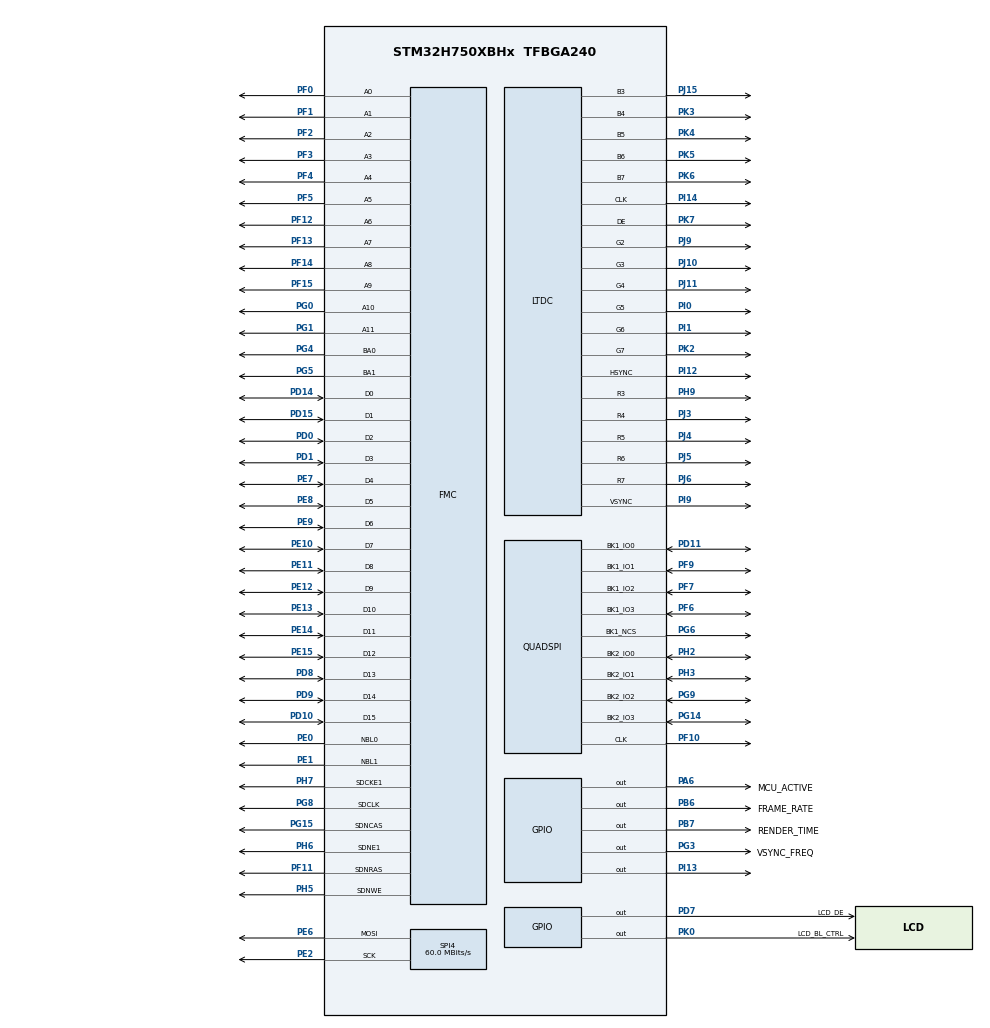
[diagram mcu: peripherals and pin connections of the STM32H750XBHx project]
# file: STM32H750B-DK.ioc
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CORTEX_M7.AccessPermission-Cortex_Memory_Protection_Unit_Region0_Settings=MPU_REGION_FULL_ACCESS
CORTEX_M7.AccessPermission-Cortex_Memory_Protection_Unit_Region1_Settings=MPU_REGION_NO_ACCESS
CORTEX_M7.AccessPermission-Cortex_Memory_Protection_Unit_Region2_Settings=MPU_REGION_FULL_ACCESS
CORTEX_M7.AccessPermission-Cortex_Memory_Protection_Unit_Region4_Settings=MPU_REGION_FULL_ACCESS
CORTEX_M7.BaseAddress-Cortex_Memory_Protection_Unit_Region0_Settings=0x24000000
CORTEX_M7.BaseAddress-Cortex_Memory_Protection_Unit_Region1_Settings=0x90000000
CORTEX_M7.BaseAddress-Cortex_Memory_Protection_Unit_Region2_Settings=0x90000000
CORTEX_M7.BaseAddress-Cortex_Memory_Protection_Unit_Region3_Settings=0xD0000000
CORTEX_M7.BaseAddress-Cortex_Memory_Protection_Unit_Region4_Settings=0xD0000000
CORTEX_M7.CPU_DCache=Enabled
CORTEX_M7.CPU_ICache=Enabled
CORTEX_M7.DisableExec-Cortex_Memory_Protection_Unit_Region0_Settings=MPU_INSTRUCTION_ACCESS_DISABLE
CORTEX_M7.DisableExec-Cortex_Memory_Protection_Unit_Region1_Settings=MPU_INSTRUCTION_ACCESS_DISABLE
CORTEX_M7.DisableExec-Cortex_Memory_Protection_Unit_Region2_Settings=MPU_INSTRUCTION_ACCESS_ENABLE
CORTEX_M7.DisableExec-Cortex_Memory_Protection_Unit_Region3_Settings=MPU_INSTRUCTION_ACCESS_DISABLE
CORTEX_M7.DisableExec-Cortex_Memory_Protection_Unit_Region4_Settings=MPU_INSTRUCTION_ACCESS_DISABLE
CORTEX_M7.Enable-Cortex_Memory_Protection_Unit_Region0_Settings=MPU_REGION_ENABLE
CORTEX_M7.Enable-Cortex_Memory_Protection_Unit_Region1_Settings=MPU_REGION_ENABLE
CORTEX_M7.Enable-Cortex_Memory_Protection_Unit_Region2_Settings=MPU_REGION_ENABLE
CORTEX_M7.Enable-Cortex_Memory_Protection_Unit_Region3_Settings=MPU_REGION_ENABLE
CORTEX_M7.Enable-Cortex_Memory_Protection_Unit_Region4_Settings=MPU_REGION_ENABLE
CORTEX_M7.IsBufferable-Cortex_Memory_Protection_Unit_Region0_Settings=MPU_ACCESS_BUFFERABLE
CORTEX_M7.IsBufferable-Cortex_Memory_Protection_Unit_Region1_Settings=MPU_ACCESS_NOT_BUFFERABLE
CORTEX_M7.IsBufferable-Cortex_Memory_Protection_Unit_Region2_Settings=MPU_ACCESS_BUFFERABLE
CORTEX_M7.IsCacheable-Cortex_Memory_Protection_Unit_Region0_Settings=MPU_ACCESS_CACHEABLE
CORTEX_M7.IsCacheable-Cortex_Memory_Protection_Unit_Region1_Settings=MPU_ACCESS_NOT_CACHEABLE
CORTEX_M7.IsCacheable-Cortex_Memory_Protection_Unit_Region2_Settings=MPU_ACCESS_CACHEABLE
CORTEX_M7.IsCacheable-Cortex_Memory_Protection_Unit_Region4_Settings=MPU_ACCESS_CACHEABLE
CORTEX_M7.IsShareable-Cortex_Memory_Protection_Unit_Region2_Settings=MPU_ACCESS_NOT_SHAREABLE
CORTEX_M7.IsShareable-Cortex_Memory_Protection_Unit_Region4_Settings=MPU_ACCESS_NOT_SHAREABLE
CORTEX_M7.MPU_Control=MPU_PRIVILEGED_DEFAULT
CORTEX_M7.Size-Cortex_Memory_Protection_Unit_Region0_Settings=MPU_REGION_SIZE_512KB
CORTEX_M7.Size-Cortex_Memory_Protection_Unit_Region1_Settings=MPU_REGION_SIZE_256MB
CORTEX_M7.Size-Cortex_Memory_Protection_Unit_Region2_Settings=MPU_REGION_SIZE_128MB
CORTEX_M7.Size-Cortex_Memory_Protection_Unit_Region3_Settings=MPU_REGION_SIZE_256MB
CORTEX_M7.Size-Cortex_Memory_Protection_Unit_Region4_Settings=MPU_REGION_SIZE_32MB
DMA2D.ColorMode=DMA2D_OUTPUT_RGB565
FMC.CASLatency2=FMC_SDRAM_CAS_LATENCY_3
FMC.ColumnBitsNumber2=FMC_SDRAM_COLUMN_BITS_NUM_8
FMC.ExitSelfRefreshDelay2=7
FMC.LoadToActiveDelay2=2
FMC.RCDDelay2=2
FMC.RPDelay2=2
FMC.ReadBurst2=FMC_SDRAM_RBURST_ENABLE
FMC.RowCycleDelay2=7
FMC.SDClockPeriod2=FMC_SDRAM_CLOCK_PERIOD_2
FMC.SelfRefreshTime2=4
FMC.WriteRecoveryTime2=5
FREERTOS.HEAP_NUMBER=4
FREERTOS.Queues01=noteQueue,16,uint8_t,0,Dynamic,NULL,NULL
FREERTOS.Tasks01=defaultTask,24,128,StartDefaultTask,Default,NULL,Dynamic,NULL,NULL;GUITask,24,8192,TouchGFX_Task,As external,NULL,Dynamic,NULL,NULL;playNoteTask,8,128,playNoteTaskFunction,Default,NULL,Dynamic,NULL,NULL
FREERTOS.configTOTAL_HEAP_SIZE=100000
FREERTOS.configUSE_APPLICATION_TASK_TAG=1
FREERTOS.configUSE_IDLE_HOOK=1
FREERTOS.configUSE_MALLOC_FAILED_HOOK=0
JPEG.JPEG_RGB_FORMAT=JPEG_RGB565
LIBJPEG.RGB_ORDERING=BGR
LTDC.ActiveH=272
LTDC.ActiveW=480
LTDC.Alpha_L0=255
LTDC.BlendingFactor1_L0=LTDC_BLENDING_FACTOR1_CA
LTDC.BlendingFactor2_L0=LTDC_BLENDING_FACTOR2_CA
LTDC.HBP=3
LTDC.HSync=40
LTDC.ImageHeight_L0=272
LTDC.ImageWidth_L0=480
LTDC.Layers=0
LTDC.PixelFormat_L0=LTDC_PIXEL_FORMAT_RGB565
LTDC.VBP=3
LTDC.VSync=9
LTDC.WindowX1_L0=480
LTDC.WindowY1_L0=272
Mcu.Family=STM32H7
Mcu.Name=STM32H750XBHx
Mcu.Package=TFBGA240
Mdma.MDMA_Channel6.JPEG_OUTFIFO_TH.0.BlockCount=0
Mdma.MDMA_Channel6.JPEG_OUTFIFO_TH.0.BlockDataLength=0
Mdma.MDMA_Channel6.JPEG_OUTFIFO_TH.0.BufferTransferLength=32
Mdma.MDMA_Channel6.JPEG_OUTFIFO_TH.0.CircularMode=MDMA_LINEAR_LIST
Mdma.MDMA_Channel6.JPEG_OUTFIFO_TH.0.DataAlignment=MDMA_DATAALIGN_PACKENABLE
Mdma.MDMA_Channel6.JPEG_OUTFIFO_TH.0.DestBlockAddressOffset=0
Mdma.MDMA_Channel6.JPEG_OUTFIFO_TH.0.DestBurst=MDMA_DEST_BURST_32BEATS
Mdma.MDMA_Channel6.JPEG_OUTFIFO_TH.0.DestDataSize=MDMA_DEST_DATASIZE_BYTE
Mdma.MDMA_Channel6.JPEG_OUTFIFO_TH.0.DestinationInc=MDMA_DEST_INC_BYTE
Mdma.MDMA_Channel6.JPEG_OUTFIFO_TH.0.DstAddress=0
Mdma.MDMA_Channel6.JPEG_OUTFIFO_TH.0.Endianness=MDMA_LITTLE_ENDIANNESS_PRESERVE
Mdma.MDMA_Channel6.JPEG_OUTFIFO_TH.0.Instance=MDMA_Channel6
Mdma.MDMA_Channel6.JPEG_OUTFIFO_TH.0.MaskAddress=0
Mdma.MDMA_Channel6.JPEG_OUTFIFO_TH.0.MaskData=0
Mdma.MDMA_Channel6.JPEG_OUTFIFO_TH.0.Priority=MDMA_PRIORITY_VERY_HIGH
Mdma.MDMA_Channel6.JPEG_OUTFIFO_TH.0.Rank=First
Mdma.MDMA_Channel6.JPEG_OUTFIFO_TH.0.SourceBlockAddressOffset=0
Mdma.MDMA_Channel6.JPEG_OUTFIFO_TH.0.SourceBurst=MDMA_SOURCE_BURST_32BEATS
Mdma.MDMA_Channel6.JPEG_OUTFIFO_TH.0.SourceDataSize=MDMA_SRC_DATASIZE_WORD
Mdma.MDMA_Channel6.JPEG_OUTFIFO_TH.0.SourceInc=MDMA_SRC_INC_DISABLE
Mdma.MDMA_Channel6.JPEG_OUTFIFO_TH.0.SrcAddress=0
Mdma.MDMA_Channel6.JPEG_OUTFIFO_TH.0.TransferTriggerMode=MDMA_BUFFER_TRANSFER
Mdma.MDMA_Channel6.Request0=JPEG_OUTFIFO_TH
Mdma.MDMA_Channel6.RequestsNb=1
Mdma.MDMA_Channel7.JPEG_INFIFO_TH.0.BlockCount=0
Mdma.MDMA_Channel7.JPEG_INFIFO_TH.0.BlockDataLength=0
Mdma.MDMA_Channel7.JPEG_INFIFO_TH.0.BufferTransferLength=32
Mdma.MDMA_Channel7.JPEG_INFIFO_TH.0.CircularMode=MDMA_LINEAR_LIST
Mdma.MDMA_Channel7.JPEG_INFIFO_TH.0.DataAlignment=MDMA_DATAALIGN_PACKENABLE
Mdma.MDMA_Channel7.JPEG_INFIFO_TH.0.DestBlockAddressOffset=0
Mdma.MDMA_Channel7.JPEG_INFIFO_TH.0.DestBurst=MDMA_DEST_BURST_16BEATS
Mdma.MDMA_Channel7.JPEG_INFIFO_TH.0.DestDataSize=MDMA_DEST_DATASIZE_WORD
Mdma.MDMA_Channel7.JPEG_INFIFO_TH.0.DestinationInc=MDMA_DEST_INC_DISABLE
Mdma.MDMA_Channel7.JPEG_INFIFO_TH.0.DstAddress=0
Mdma.MDMA_Channel7.JPEG_INFIFO_TH.0.Endianness=MDMA_LITTLE_ENDIANNESS_PRESERVE
Mdma.MDMA_Channel7.JPEG_INFIFO_TH.0.Instance=MDMA_Channel7
Mdma.MDMA_Channel7.JPEG_INFIFO_TH.0.MaskAddress=0
Mdma.MDMA_Channel7.JPEG_INFIFO_TH.0.MaskData=0
Mdma.MDMA_Channel7.JPEG_INFIFO_TH.0.Priority=MDMA_PRIORITY_HIGH
Mdma.MDMA_Channel7.JPEG_INFIFO_TH.0.Rank=First
Mdma.MDMA_Channel7.JPEG_INFIFO_TH.0.SourceBlockAddressOffset=0
Mdma.MDMA_Channel7.JPEG_INFIFO_TH.0.SourceBurst=MDMA_SOURCE_BURST_32BEATS
Mdma.MDMA_Channel7.JPEG_INFIFO_TH.0.SourceDataSize=MDMA_SRC_DATASIZE_BYTE
Mdma.MDMA_Channel7.JPEG_INFIFO_TH.0.SourceInc=MDMA_SRC_INC_BYTE
Mdma.MDMA_Channel7.JPEG_INFIFO_TH.0.SrcAddress=0
Mdma.MDMA_Channel7.JPEG_INFIFO_TH.0.TransferTriggerMode=MDMA_BUFFER_TRANSFER
Mdma.MDMA_Channel7.Request0=JPEG_INFIFO_TH
Mdma.MDMA_Channel7.RequestsNb=1
Mdma.RequestSet0=MDMA_Channel7
Mdma.RequestSet1=MDMA_Channel6
Mdma.RequestSetsNb=2
NVIC.DMA2D_IRQn=true\:5\:0\:true\:false\:true\:false\:true\:true\:true
NVIC.JPEG_IRQn=true\:5\:0\:false\:false\:true\:true\:true\:true\:true
NVIC.LTDC_IRQn=true\:5\:0\:true\:false\:true\:false\:true\:true\:true
NVIC.MDMA_IRQn=true\:5\:0\:false\:false\:true\:true\:false\:true\:true
NVIC.PriorityGroup=NVIC_PRIORITYGROUP_4
NVIC.TIM5_IRQn=true\:5\:0\:false\:false\:true\:true\:true\:true\:true
NVIC.TIM6_DAC_IRQn=true\:0\:0\:false\:false\:true\:false\:false\:true\:true
NVIC.TimeBase=TIM6_DAC_IRQn
NVIC.TimeBaseIP=TIM6
PA6.GPIO_Label=MCU_ACTIVE
PA6.GPIO_Speed=GPIO_SPEED_FREQ_VERY_HIGH
PA6.Signal=GPIO_Output
PB6.GPIO_Label=FRAME_RATE
PB6.GPIO_Speed=GPIO_SPEED_FREQ_VERY_HIGH
PB6.Signal=GPIO_Output
PB7.GPIO_Label=RENDER_TIME
PB7.GPIO_Speed=GPIO_SPEED_FREQ_VERY_HIGH
PB7.Signal=GPIO_Output
PD0.Signal=FMC_D2_DA2
PD1.Signal=FMC_D3_DA3
PD10.Signal=FMC_D15_DA15
PD11.GPIO_Speed=GPIO_SPEED_FREQ_VERY_HIGH
PD11.Mode=Dual_Bank
PD11.Signal=QUADSPI_BK1_IO0
PD14.Signal=FMC_D0_DA0
PD15.Signal=FMC_D1_DA1
PD7.GPIO_Label=LCD_DE
PD7.Signal=GPIO_Output
PD8.Signal=FMC_D13_DA13
PD9.Signal=FMC_D14_DA14
PE0.Signal=FMC_NBL0
PE1.Signal=FMC_NBL1
PE10.Signal=FMC_D7_DA7
PE11.Signal=FMC_D8_DA8
PE12.Signal=FMC_D9_DA9
PE13.Signal=FMC_D10_DA10
PE14.Signal=FMC_D11_DA11
PE15.Signal=FMC_D12_DA12
PE2.Mode=TX_Only_Simplex_Unidirect_Master
PE2.Signal=SPI4_SCK
PE6.Mode=TX_Only_Simplex_Unidirect_Master
PE6.Signal=SPI4_MOSI
PE7.Signal=FMC_D4_DA4
PE8.Signal=FMC_D5_DA5
PE9.Signal=FMC_D6_DA6
PF0.Signal=FMC_A0
PF1.Signal=FMC_A1
PF10.GPIO_Speed=GPIO_SPEED_FREQ_VERY_HIGH
PF10.Mode=Dual_Bank
PF10.Signal=QUADSPI_CLK
PF11.Signal=FMC_SDNRAS
PF12.Signal=FMC_A6
PF13.Signal=FMC_A7
PF14.Signal=FMC_A8
PF15.Signal=FMC_A9
PF2.Signal=FMC_A2
PF3.Signal=FMC_A3
PF4.Signal=FMC_A4
PF5.Signal=FMC_A5
PF6.GPIO_Speed=GPIO_SPEED_FREQ_VERY_HIGH
PF6.Mode=Dual_Bank
PF6.Signal=QUADSPI_BK1_IO3
PF7.GPIO_Speed=GPIO_SPEED_FREQ_VERY_HIGH
PF7.Mode=Dual_Bank
PF7.Signal=QUADSPI_BK1_IO2
PF9.GPIO_Speed=GPIO_SPEED_FREQ_VERY_HIGH
PF9.Mode=Dual_Bank
PF9.Signal=QUADSPI_BK1_IO1
PG0.Signal=FMC_A10
PG1.Signal=FMC_A11
PG14.GPIO_Speed=GPIO_SPEED_FREQ_VERY_HIGH
PG14.Mode=Dual_Bank
PG14.Signal=QUADSPI_BK2_IO3
PG15.Signal=FMC_SDNCAS
PG3.GPIO_Label=VSYNC_FREQ
PG3.GPIO_Speed=GPIO_SPEED_FREQ_VERY_HIGH
PG3.Signal=GPIO_Output
PG4.Signal=FMC_A14_BA0
PG5.Signal=FMC_A15_BA1
PG6.GPIO_Speed=GPIO_SPEED_FREQ_VERY_HIGH
PG6.Mode=Enable Chip Select 1 for both banks
PG6.Signal=QUADSPI_BK1_NCS
PG8.Signal=FMC_SDCLK
PG9.GPIO_Speed=GPIO_SPEED_FREQ_VERY_HIGH
PG9.Mode=Dual_Bank
PG9.Signal=QUADSPI_BK2_IO2
PH0-OSC_IN\ (PH0).Mode=HSE-External-Oscillator
PH0-OSC_IN\ (PH0).Signal=RCC_OSC_IN
PH1-OSC_OUT\ (PH1).Mode=HSE-External-Oscillator
PH1-OSC_OUT\ (PH1).Signal=RCC_OSC_OUT
PH2.GPIO_Speed=GPIO_SPEED_FREQ_VERY_HIGH
PH2.Mode=Dual_Bank
PH2.Signal=QUADSPI_BK2_IO0
PH3.GPIO_Speed=GPIO_SPEED_FREQ_VERY_HIGH
PH3.Mode=Dual_Bank
PH3.Signal=QUADSPI_BK2_IO1
PH5.Signal=FMC_SDNWE
PH6.Mode=SdramChipSelect2_2
PH6.Signal=FMC_SDNE1
PH7.Mode=SdramChipSelect2_2
PH7.Signal=FMC_SDCKE1
PH9.GPIO_Speed=GPIO_SPEED_FREQ_HIGH
PH9.Mode=RGB565
PH9.Signal=LTDC_R3
PI0.GPIO_Speed=GPIO_SPEED_FREQ_HIGH
PI0.Mode=RGB565
PI0.Signal=LTDC_G5
PI1.GPIO_Speed=GPIO_SPEED_FREQ_HIGH
PI1.Mode=RGB565
PI1.Signal=LTDC_G6
PI12.GPIO_Speed=GPIO_SPEED_FREQ_HIGH
PI12.Mode=RGB565
PI12.Signal=LTDC_HSYNC
PI13.GPIO_ModeDefaultOutputPP=GPIO_MODE_OUTPUT_PP
PI13.Signal=GPIO_Output
PI14.GPIO_Speed=GPIO_SPEED_FREQ_HIGH
PI14.Mode=RGB565
PI14.Signal=LTDC_CLK
PI15.GPIO_Speed=GPIO_SPEED_FREQ_HIGH
PI15.Signal=LTDC_R0
PI9.GPIO_Speed=GPIO_SPEED_FREQ_HIGH
PI9.Mode=RGB565
PI9.Signal=LTDC_VSYNC
PJ0.GPIO_Speed=GPIO_SPEED_FREQ_HIGH
PJ0.Signal=LTDC_R1
PJ1.GPIO_Speed=GPIO_SPEED_FREQ_HIGH
PJ1.Signal=LTDC_R2
PJ10.GPIO_Speed=GPIO_SPEED_FREQ_HIGH
PJ10.Mode=RGB565
PJ10.Signal=LTDC_G3
PJ11.GPIO_Speed=GPIO_SPEED_FREQ_HIGH
PJ11.Mode=RGB565
PJ11.Signal=LTDC_G4
PJ12.GPIO_Speed=GPIO_SPEED_FREQ_HIGH
PJ12.Signal=LTDC_B0
PJ13.GPIO_Speed=GPIO_SPEED_FREQ_HIGH
PJ13.Signal=LTDC_B1
PJ14.GPIO_Speed=GPIO_SPEED_FREQ_HIGH
PJ14.Signal=LTDC_B2
PJ15.GPIO_Speed=GPIO_SPEED_FREQ_HIGH
PJ15.Mode=RGB565
PJ15.Signal=LTDC_B3
PJ3.GPIO_Speed=GPIO_SPEED_FREQ_HIGH
PJ3.Mode=RGB565
PJ3.Signal=LTDC_R4
PJ4.GPIO_Speed=GPIO_SPEED_FREQ_HIGH
PJ4.Mode=RGB565
PJ4.Signal=LTDC_R5
PJ5.GPIO_Speed=GPIO_SPEED_FREQ_HIGH
PJ5.Mode=RGB565
PJ5.Signal=LTDC_R6
PJ6.GPIO_Speed=GPIO_SPEED_FREQ_HIGH
PJ6.Mode=RGB565
PJ6.Signal=LTDC_R7
PJ7.GPIO_Speed=GPIO_SPEED_FREQ_HIGH
PJ7.Signal=LTDC_G0
PJ8.GPIO_Speed=GPIO_SPEED_FREQ_HIGH
PJ8.Signal=LTDC_G1
PJ9.GPIO_Speed=GPIO_SPEED_FREQ_HIGH
PJ9.Mode=RGB565
PJ9.Signal=LTDC_G2
PK0.GPIO_Label=LCD_BL_CTRL
PK0.PinState=GPIO_PIN_SET
PK0.Signal=GPIO_Output
PK2.GPIO_Speed=GPIO_SPEED_FREQ_HIGH
PK2.Mode=RGB565
PK2.Signal=LTDC_G7
PK3.GPIO_Speed=GPIO_SPEED_FREQ_HIGH
PK3.Mode=RGB565
PK3.Signal=LTDC_B4
PK4.GPIO_Speed=GPIO_SPEED_FREQ_HIGH
PK4.Mode=RGB565
PK4.Signal=LTDC_B5
PK5.GPIO_Speed=GPIO_SPEED_FREQ_HIGH
PK5.Mode=RGB565
PK5.Signal=LTDC_B6
PK6.GPIO_Speed=GPIO_SPEED_FREQ_HIGH
PK6.Mode=RGB565
PK6.Signal=LTDC_B7
PK7.GPIO_Speed=GPIO_SPEED_FREQ_HIGH
PK7.Mode=RGB565
PK7.Signal=LTDC_DE
ProjectManager.HeapSize=0x1000
ProjectManager.StackSize=0x1000
ProjectManager.TargetToolchain=STM32CubeIDE
QUADSPI.ChipSelectHighTime=QSPI_CS_HIGH_TIME_4_CYCLE
QUADSPI.ClockMode=QSPI_CLOCK_MODE_0
QUADSPI.ClockPrescaler=3
QUADSPI.FlashSize=26
QUADSPI.SampleShifting=QSPI_SAMPLE_SHIFTING_NONE
RCC.ADCFreq_Value=50390625
RCC.APB1Freq_Value=120000000
RCC.APB2Freq_Value=120000000
RCC.APB3Freq_Value=120000000
RCC.APB4Freq_Value=120000000
RCC.CortexFreq_Value=480000000
RCC.D1PPRE=RCC_APB3_DIV2
RCC.D2PPRE1=RCC_APB1_DIV2
RCC.D2PPRE2=RCC_APB2_DIV2
RCC.D3PPRE=RCC_APB4_DIV2
RCC.DIVM1=5
RCC.DIVM3=5
RCC.DIVN1=192
RCC.DIVN3=160
RCC.DIVQ1=4
RCC.DIVR3=93
RCC.HCLKFreq_Value=240000000
RCC.HPRE=RCC_HCLK_DIV2
RCC.PLL3FRACN=0
RCC.PLLSourceVirtual=RCC_PLLSOURCE_HSE
RCC.SYSCLKFreq_VALUE=480000000
RCC.SYSCLKSource=RCC_SYSCLKSOURCE_PLLCLK
RCC.USBFreq_Value=240000000
SH.FMC_A0.0=FMC_A0,12b-sda2
SH.FMC_A1.0=FMC_A1,12b-sda2
SH.FMC_A10.0=FMC_A10,12b-sda2
SH.FMC_A11.0=FMC_A11,12b-sda2
SH.FMC_A14_BA0.0=FMC_BA0,FourSdramBanks2
SH.FMC_A15_BA1.0=FMC_BA1,FourSdramBanks2
SH.FMC_A2.0=FMC_A2,12b-sda2
SH.FMC_A3.0=FMC_A3,12b-sda2
SH.FMC_A4.0=FMC_A4,12b-sda2
SH.FMC_A5.0=FMC_A5,12b-sda2
SH.FMC_A6.0=FMC_A6,12b-sda2
SH.FMC_A7.0=FMC_A7,12b-sda2
SH.FMC_A8.0=FMC_A8,12b-sda2
SH.FMC_A9.0=FMC_A9,12b-sda2
SH.FMC_D0_DA0.0=FMC_D0,sd-16b-d2
SH.FMC_D10_DA10.0=FMC_D10,sd-16b-d2
SH.FMC_D11_DA11.0=FMC_D11,sd-16b-d2
SH.FMC_D12_DA12.0=FMC_D12,sd-16b-d2
SH.FMC_D13_DA13.0=FMC_D13,sd-16b-d2
SH.FMC_D14_DA14.0=FMC_D14,sd-16b-d2
SH.FMC_D15_DA15.0=FMC_D15,sd-16b-d2
SH.FMC_D1_DA1.0=FMC_D1,sd-16b-d2
SH.FMC_D2_DA2.0=FMC_D2,sd-16b-d2
SH.FMC_D3_DA3.0=FMC_D3,sd-16b-d2
SH.FMC_D4_DA4.0=FMC_D4,sd-16b-d2
SH.FMC_D5_DA5.0=FMC_D5,sd-16b-d2
SH.FMC_D6_DA6.0=FMC_D6,sd-16b-d2
SH.FMC_D7_DA7.0=FMC_D7,sd-16b-d2
SH.FMC_D8_DA8.0=FMC_D8,sd-16b-d2
SH.FMC_D9_DA9.0=FMC_D9,sd-16b-d2
SH.FMC_NBL0.0=FMC_NBL0,Sd2ByteEnable2
SH.FMC_NBL1.0=FMC_NBL1,Sd2ByteEnable2
SH.FMC_SDCLK.0=FMC_SDCLK,12b-sda2
SH.FMC_SDNCAS.0=FMC_SDNCAS,12b-sda2
SH.FMC_SDNRAS.0=FMC_SDNRAS,12b-sda2
SH.FMC_SDNWE.0=FMC_SDNWE,12b-sda2
SPI4.CalculateBaudRate=60.0 MBits/s
SPI4.Direction=SPI_DIRECTION_2LINES_TXONLY
SPI4.Mode=SPI_MODE_MASTER
SPI4.VirtualType=VM_MASTER
STMicroelectronics.X-CUBE-TOUCHGFX.4.24.0.ApplicationCcGraphicsJjApplication=TouchGFXOoGenerator
STMicroelectronics.X-CUBE-TOUCHGFX.4.24.0.tgfx_address1=0xD0000000
STMicroelectronics.X-CUBE-TOUCHGFX.4.24.0.tgfx_address2=0xD003FC00
STMicroelectronics.X-CUBE-TOUCHGFX.4.24.0.tgfx_buffering_strategy=Double
STMicroelectronics.X-CUBE-TOUCHGFX.4.24.0.tgfx_display_interface=disp_ltdc
STMicroelectronics.X-CUBE-TOUCHGFX.4.24.0.tgfx_hardware_accelerator=dma_2d
STMicroelectronics.X-CUBE-TOUCHGFX.4.24.0.tgfx_location=Allocate
STMicroelectronics.X-CUBE-TOUCHGFX.4.24.0.tgfx_pixel_format=RGB565\:16
STMicroelectronics.X-CUBE-TOUCHGFX.4.24.0.tgfx_vector_fonts=Enabled
STMicroelectronics.X-CUBE-TOUCHGFX.4.24.0.tgfx_vector_rendering=Software
STMicroelectronics.X-CUBE-TOUCHGFX.4.24.0.tgfx_video=Hardware
STMicroelectronics.X-CUBE-TOUCHGFX.4.24.0.tgfx_video_height=288
STMicroelectronics.X-CUBE-TOUCHGFX.4.24.0.tgfx_video_strategy=0
STMicroelectronics.X-CUBE-TOUCHGFX.4.24.0.tgfx_video_width=480
STMicroelectronics.X-CUBE-TOUCHGFX.4.24.0.tgfx_vsync=vsync_ltdc
TIM5.AutoReloadPreload=TIM_AUTORELOAD_PRELOAD_ENABLE
VP_CRC_VS_CRC.Mode=CRC_Activate
VP_DMA2D_VS_DMA2D.Mode=DMA2D_Activate
VP_FREERTOS_VS_CMSIS_V2.Mode=CMSIS_V2
VP_JPEG_VS_JPEG.Mode=JPEG_Activate
VP_LIBJPEG_VS_JPEGLIB.Mode=Enabled
VP_MEMORYMAP_VS_MEMORYMAP.Mode=CurAppReg
VP_STMicroelectronics.X-CUBE-TOUCHGFX_VS_GraphicsJjApplication_4.24.0.Mode=GraphicsJjApplication
VP_SYS_VS_tim6.Mode=TIM6
VP_TIM1_VS_ClockSourceINT.Mode=Internal
VP_TIM5_VS_ClockSourceINT.Mode=Internal
board=custom

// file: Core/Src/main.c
/* USER CODE BEGIN Header */
/**
  ******************************************************************************
  * @file           : main.c
  * @brief          : Main program body
  ******************************************************************************
  * @attention
  *
  * <h2><center>&copy; Copyright (c) 2020 STMicroelectronics.
  * All rights reserved.</center></h2>
  *
  * This software component is licensed by ST under Ultimate Liberty license
  * SLA0044, the "License"; You may not use this file except in compliance with
  * the License. You may obtain a copy of the License at:
  *                             www.st.com/SLA0044
  *
  ******************************************************************************
  */
/* USER CODE END Header */
#include "main.h"
#include "cmsis_os.h"
#include "libjpeg.h"
#include "app_touchgfx.h"

/* USER CODE BEGIN Includes */
#include "stm32h750b_discovery_qspi.h"
#include "stm32h750b_discovery_sdram.h"
/* USER CODE END Includes */

/* USER CODE BEGIN PTD */
#define F_SAMP 20000
#define ARR_SIZE 1024

/* USER CODE END PTD */

/* USER CODE BEGIN PM */
uint32_t bitmask;
uint16_t start;
uint32_t outData = 0x8000;
uint32_t tableIndex = 0;
uint32_t step = 0;
uint16_t state = 0;

const uint16_t sine_table[1024] = {
0x7FFF,0x80C8,0x8191,0x825A,0x8323,0x83EC,0x84B5,
0x857E,0x8647,0x8710,0x87D8,0x88A1,0x8969,0x8A32,
0x8AFA,0x8BC3,0x8C8B,0x8D53,0x8E1B,0x8EE2,0x8FAA,
0x9071,0x9139,0x9200,0x92C7,0x938E,0x9454,0x951B,
0x95E1,0x96A7,0x976D,0x9832,0x98F8,0x99BD,0x9A81,
0x9B46,0x9C0A,0x9CCE,0x9D92,0x9E56,0x9F19,0x9FDC,
0xA09E,0xA160,0xA222,0xA2E4,0xA3A5,0xA466,0xA527,
0xA5E7,0xA6A7,0xA766,0xA825,0xA8E4,0xA9A2,0xAA60,
0xAB1E,0xABDB,0xAC98,0xAD54,0xAE10,0xAECB,0xAF86,
0xB040,0xB0FA,0xB1B4,0xB26D,0xB325,0xB3DE,0xB495,
0xB54C,0xB603,0xB6B9,0xB76E,0xB823,0xB8D8,0xB98B,
0xBA3F,0xBAF1,0xBBA4,0xBC55,0xBD06,0xBDB7,0xBE67,
0xBF16,0xBFC4,0xC072,0xC120,0xC1CD,0xC279,0xC324,
0xC3CF,0xC479,0xC523,0xC5CC,0xC674,0xC71B,0xC7C2,
0xC868,0xC90E,0xC9B3,0xCA57,0xCAFA,0xCB9C,0xCC3E,
0xCCDF,0xCD80,0xCE1F,0xCEBE,0xCF5C,0xCFFA,0xD096,
0xD132,0xD1CD,0xD267,0xD301,0xD39A,0xD431,0xD4C8,
0xD55F,0xD5F4,0xD689,0xD71C,0xD7AF,0xD841,0xD8D2,
0xD963,0xD9F2,0xDA81,0xDB0E,0xDB9B,0xDC27,0xDCB2,
0xDD3D,0xDDC6,0xDE4E,0xDED6,0xDF5C,0xDFE2,0xE067,
0xE0EA,0xE16D,0xE1EF,0xE270,0xE2F0,0xE36F,0xE3ED,
0xE46B,0xE4E7,0xE562,0xE5DC,0xE655,0xE6CE,0xE745,
0xE7BB,0xE831,0xE8A5,0xE918,0xE98A,0xE9FC,0xEA6C,
0xEADB,0xEB49,0xEBB6,0xEC22,0xEC8D,0xECF7,0xED60,
0xEDC8,0xEE2F,0xEE95,0xEEFA,0xEF5D,0xEFC0,0xF021,
0xF082,0xF0E1,0xF13F,0xF19C,0xF1F8,0xF253,0xF2AD,
0xF306,0xF35D,0xF3B4,0xF409,0xF45E,0xF4B1,0xF503,
0xF554,0xF5A4,0xF5F2,0xF640,0xF68C,0xF6D7,0xF721,
0xF76A,0xF7B2,0xF7F9,0xF83E,0xF883,0xF8C6,0xF908,
0xF949,0xF988,0xF9C7,0xFA04,0xFA40,0xFA7B,0xFAB5,
0xFAED,0xFB25,0xFB5B,0xFB90,0xFBC4,0xFBF7,0xFC28,
0xFC58,0xFC87,0xFCB5,0xFCE2,0xFD0D,0xFD38,0xFD61,
0xFD88,0xFDAF,0xFDD4,0xFDF9,0xFE1C,0xFE3D,0xFE5E,
0xFE7D,0xFE9B,0xFEB8,0xFED4,0xFEEE,0xFF08,0xFF20,
0xFF36,0xFF4C,0xFF60,0xFF73,0xFF85,0xFF96,0xFFA5,
0xFFB3,0xFFC0,0xFFCC,0xFFD7,0xFFE0,0xFFE8,0xFFEF,
0xFFF4,0xFFF8,0xFFFC,0xFFFD,0xFFFE,0xFFFD,0xFFFC,
0xFFF8,0xFFF4,0xFFEF,0xFFE8,0xFFE0,0xFFD7,0xFFCC,
0xFFC0,0xFFB3,0xFFA5,0xFF96,0xFF85,0xFF73,0xFF60,
0xFF4C,0xFF36,0xFF20,0xFF08,0xFEEE,0xFED4,0xFEB8,
0xFE9B,0xFE7D,0xFE5E,0xFE3D,0xFE1C,0xFDF9,0xFDD4,
0xFDAF,0xFD88,0xFD61,0xFD38,0xFD0D,0xFCE2,0xFCB5,
0xFC87,0xFC58,0xFC28,0xFBF7,0xFBC4,0xFB90,0xFB5B,
0xFB25,0xFAED,0xFAB5,0xFA7B,0xFA40,0xFA04,0xF9C7,
0xF988,0xF949,0xF908,0xF8C6,0xF883,0xF83E,0xF7F9,
0xF7B2,0xF76A,0xF721,0xF6D7,0xF68C,0xF640,0xF5F2,
0xF5A4,0xF554,0xF503,0xF4B1,0xF45E,0xF409,0xF3B4,
0xF35D,0xF306,0xF2AD,0xF253,0xF1F8,0xF19C,0xF13F,
0xF0E1,0xF082,0xF021,0xEFC0,0xEF5D,0xEEFA,0xEE95,
0xEE2F,0xEDC8,0xED60,0xECF7,0xEC8D,0xEC22,0xEBB6,
0xEB49,0xEADB,0xEA6C,0xE9FC,0xE98A,0xE918,0xE8A5,
0xE831,0xE7BB,0xE745,0xE6CE,0xE655,0xE5DC,0xE562,
0xE4E7,0xE46B,0xE3ED,0xE36F,0xE2F0,0xE270,0xE1EF,
0xE16D,0xE0EA,0xE067,0xDFE2,0xDF5C,0xDED6,0xDE4E,
0xDDC6,0xDD3D,0xDCB2,0xDC27,0xDB9B,0xDB0E,0xDA81,
0xD9F2,0xD963,0xD8D2,0xD841,0xD7AF,0xD71C,0xD689,
0xD5F4,0xD55F,0xD4C8,0xD431,0xD39A,0xD301,0xD267,
0xD1CD,0xD132,0xD096,0xCFFA,0xCF5C,0xCEBE,0xCE1F,
0xCD80,0xCCDF,0xCC3E,0xCB9C,0xCAFA,0xCA57,0xC9B3,
0xC90E,0xC868,0xC7C2,0xC71B,0xC674,0xC5CC,0xC523,
0xC479,0xC3CF,0xC324,0xC279,0xC1CD,0xC120,0xC072,
0xBFC4,0xBF16,0xBE67,0xBDB7,0xBD06,0xBC55,0xBBA4,
0xBAF1,0xBA3F,0xB98B,0xB8D8,0xB823,0xB76E,0xB6B9,
0xB603,0xB54C,0xB495,0xB3DE,0xB325,0xB26D,0xB1B4,
0xB0FA,0xB040,0xAF86,0xAECB,0xAE10,0xAD54,0xAC98,
0xABDB,0xAB1E,0xAA60,0xA9A2,0xA8E4,0xA825,0xA766,
0xA6A7,0xA5E7,0xA527,0xA466,0xA3A5,0xA2E4,0xA222,
0xA160,0xA09E,0x9FDC,0x9F19,0x9E56,0x9D92,0x9CCE,
0x9C0A,0x9B46,0x9A81,0x99BD,0x98F8,0x9832,0x976D,
0x96A7,0x95E1,0x951B,0x9454,0x938E,0x92C7,0x9200,
0x9139,0x9071,0x8FAA,0x8EE2,0x8E1B,0x8D53,0x8C8B,
0x8BC3,0x8AFA,0x8A32,0x8969,0x88A1,0x87D8,0x8710,
0x8647,0x857E,0x84B5,0x83EC,0x8323,0x825A,0x8191,
0x80C8,0x7FFF,0x7F36,0x7E6D,0x7DA4,0x7CDB,0x7C12,
0x7B49,0x7A80,0x79B7,0x78EE,0x7826,0x775D,0x7695,
0x75CC,0x7504,0x743B,0x7373,0x72AB,0x71E3,0x711C,
0x7054,0x6F8D,0x6EC5,0x6DFE,0x6D37,0x6C70,0x6BAA,
0x6AE3,0x6A1D,0x6957,0x6891,0x67CC,0x6706,0x6641,
0x657D,0x64B8,0x63F4,0x6330,0x626C,0x61A8,0x60E5,
0x6022,0x5F60,0x5E9E,0x5DDC,0x5D1A,0x5C59,0x5B98,
0x5AD7,0x5A17,0x5957,0x5898,0x57D9,0x571A,0x565C,
0x559E,0x54E0,0x5423,0x5366,0x52AA,0x51EE,0x5133,
0x5078,0x4FBE,0x4F04,0x4E4A,0x4D91,0x4CD9,0x4C20,
0x4B69,0x4AB2,0x49FB,0x4945,0x4890,0x47DB,0x4726,
0x4673,0x45BF,0x450D,0x445A,0x43A9,0x42F8,0x4247,
0x4197,0x40E8,0x403A,0x3F8C,0x3EDE,0x3E31,0x3D85,
0x3CDA,0x3C2F,0x3B85,0x3ADB,0x3A32,0x398A,0x38E3,
0x383C,0x3796,0x36F0,0x364B,0x35A7,0x3504,0x3462,
0x33C0,0x331F,0x327E,0x31DF,0x3140,0x30A2,0x3004,
0x2F68,0x2ECC,0x2E31,0x2D97,0x2CFD,0x2C64,0x2BCD,
0x2B36,0x2A9F,0x2A0A,0x2975,0x28E2,0x284F,0x27BD,
0x272C,0x269B,0x260C,0x257D,0x24F0,0x2463,0x23D7,
0x234C,0x22C1,0x2238,0x21B0,0x2128,0x20A2,0x201C,
0x1F97,0x1F14,0x1E91,0x1E0F,0x1D8E,0x1D0E,0x1C8F,
0x1C11,0x1B93,0x1B17,0x1A9C,0x1A22,0x19A9,0x1930,
0x18B9,0x1843,0x17CD,0x1759,0x16E6,0x1674,0x1602,
0x1592,0x1523,0x14B5,0x1448,0x13DC,0x1371,0x1307,
0x129E,0x1236,0x11CF,0x1169,0x1104,0x10A1,0x103E,
0x0FDD,0x0F7C,0x0F1D,0x0EBF,0x0E62,0x0E06,0x0DAB,
0x0D51,0x0CF8,0x0CA1,0x0C4A,0x0BF5,0x0BA0,0x0B4D,
0x0AFB,0x0AAA,0x0A5A,0x0A0C,0x09BE,0x0972,0x0927,
0x08DD,0x0894,0x084C,0x0805,0x07C0,0x077B,0x0738,
0x06F6,0x06B5,0x0676,0x0637,0x05FA,0x05BE,0x0583,
0x0549,0x0511,0x04D9,0x04A3,0x046E,0x043A,0x0407,
0x03D6,0x03A6,0x0377,0x0349,0x031C,0x02F1,0x02C6,
0x029D,0x0276,0x024F,0x022A,0x0205,0x01E2,0x01C1,
0x01A0,0x0181,0x0163,0x0146,0x012A,0x0110,0x00F6,
0x00DE,0x00C8,0x00B2,0x009E,0x008B,0x0079,0x0068,
0x0059,0x004B,0x003E,0x0032,0x0027,0x001E,0x0016,
0x000F,0x000A,0x0006,0x0002,0x0001,0x0000,0x0001,
0x0002,0x0006,0x000A,0x000F,0x0016,0x001E,0x0027,
0x0032,0x003E,0x004B,0x0059,0x0068,0x0079,0x008B,
0x009E,0x00B2,0x00C8,0x00DE,0x00F6,0x0110,0x012A,
0x0146,0x0163,0x0181,0x01A0,0x01C1,0x01E2,0x0205,
0x022A,0x024F,0x0276,0x029D,0x02C6,0x02F1,0x031C,
0x0349,0x0377,0x03A6,0x03D6,0x0407,0x043A,0x046E,
0x04A3,0x04D9,0x0511,0x0549,0x0583,0x05BE,0x05FA,
0x0637,0x0676,0x06B5,0x06F6,0x0738,0x077B,0x07C0,
0x0805,0x084C,0x0894,0x08DD,0x0927,0x0972,0x09BE,
0x0A0C,0x0A5A,0x0AAA,0x0AFB,0x0B4D,0x0BA0,0x0BF5,
0x0C4A,0x0CA1,0x0CF8,0x0D51,0x0DAB,0x0E06,0x0E62,
0x0EBF,0x0F1D,0x0F7C,0x0FDD,0x103E,0x10A1,0x1104,
0x1169,0x11CF,0x1236,0x129E,0x1307,0x1371,0x13DC,
0x1448,0x14B5,0x1523,0x1592,0x1602,0x1674,0x16E6,
0x1759,0x17CD,0x1843,0x18B9,0x1930,0x19A9,0x1A22,
0x1A9C,0x1B17,0x1B93,0x1C11,0x1C8F,0x1D0E,0x1D8E,
0x1E0F,0x1E91,0x1F14,0x1F97,0x201C,0x20A2,0x2128,
0x21B0,0x2238,0x22C1,0x234C,0x23D7,0x2463,0x24F0,
0x257D,0x260C,0x269B,0x272C,0x27BD,0x284F,0x28E2,
0x2975,0x2A0A,0x2A9F,0x2B36,0x2BCD,0x2C64,0x2CFD,
0x2D97,0x2E31,0x2ECC,0x2F68,0x3004,0x30A2,0x3140,
0x31DF,0x327E,0x331F,0x33C0,0x3462,0x3504,0x35A7,
0x364B,0x36F0,0x3796,0x383C,0x38E3,0x398A,0x3A32,
0x3ADB,0x3B85,0x3C2F,0x3CDA,0x3D85,0x3E31,0x3EDE,
0x3F8C,0x403A,0x40E8,0x4197,0x4247,0x42F8,0x43A9,
0x445A,0x450D,0x45BF,0x4673,0x4726,0x47DB,0x4890,
0x4945,0x49FB,0x4AB2,0x4B69,0x4C20,0x4CD9,0x4D91,
0x4E4A,0x4F04,0x4FBE,0x5078,0x5133,0x51EE,0x52AA,
0x5366,0x5423,0x54E0,0x559E,0x565C,0x571A,0x57D9,
0x5898,0x5957,0x5A17,0x5AD7,0x5B98,0x5C59,0x5D1A,
0x5DDC,0x5E9E,0x5F60,0x6022,0x60E5,0x61A8,0x626C,
0x6330,0x63F4,0x64B8,0x657D,0x6641,0x6706,0x67CC,
0x6891,0x6957,0x6A1D,0x6AE3,0x6BAA,0x6C70,0x6D37,
0x6DFE,0x6EC5,0x6F8D,0x7054,0x711C,0x71E3,0x72AB,
0x7373,0x743B,0x7504,0x75CC,0x7695,0x775D,0x7826,
0x78EE,0x79B7,0x7A80,0x7B49,0x7C12,0x7CDB,0x7DA4,
0x7E6D,0x7F36};

const uint16_t wave1_table[ARR_SIZE] = {
32767,33370,33973,34576,35177,35778,36378,36977,
37574,38169,38762,39353,39942,40528,41111,41692,
42269,42843,43413,43979,44541,45099,45652,46201,
46745,47284,47818,48347,48870,49387,49898,50404,
50903,51395,51882,52361,52834,53299,53758,54209,
54652,55089,55517,55938,56350,56755,57151,57539,
57919,58290,58653,59007,59352,59688,60016,60334,
60643,60943,61234,61516,61788,62051,62304,62548,
62783,63007,63223,63428,63625,63811,63988,64155,
64313,64460,64599,64727,64846,64956,65055,65146,
65226,65298,65359,65412,65455,65488,65513,65528,
65534,65531,65519,65498,65468,65429,65381,65325,
65260,65187,65105,65015,64917,64810,64696,64574,
64443,64305,64160,64007,63846,63679,63504,63322,
63133,62937,62735,62526,62310,62088,61860,61626,
61386,61140,60889,60631,60369,60101,59828,59550,
59266,58979,58686,58389,58088,57782,57472,57158,
56840,56519,56194,55865,55534,55199,54860,54519,
54175,53829,53479,53128,52774,52417,52059,51699,
51337,50973,50607,50240,49872,49502,49132,48760,
48387,48014,47640,47265,46889,46514,46138,45761,
45385,45009,44633,44257,43881,43505,43130,42756,
42382,42009,41637,41266,40895,40526,40158,39790,
39425,39060,38697,38335,37975,37616,37260,36904,
36551,36199,35849,35502,35156,34812,34470,34131,
33793,33458,33125,32794,32466,32140,31816,31495,
31176,30860,30547,30236,29927,29621,29318,29018,
28720,28425,28132,27843,27556,27272,26990,26712,
26436,26164,25894,25626,25362,25101,24842,24587,
24334,24084,23837,23593,23352,23114,22878,22646,
22416,22189,21966,21745,21527,21311,21099,20889,
20683,20479,20278,20080,19885,19692,19502,19315,
19131,18950,18771,18595,18422,18251,18083,17918,
17756,17596,17439,17284,17132,16983,16836,16692,
16550,16411,16274,16140,16008,15879,15752,15628,
15506,15386,15269,15154,15042,14932,14824,14718,
14615,14514,14415,14319,14225,14133,14043,13955,
13870,13786,13705,13626,13549,13474,13401,13330,
13262,13195,13130,13067,13007,12948,12891,12836,
12783,12732,12683,12636,12591,12547,12505,12466,
12428,12392,12358,12325,12294,12266,12238,12213,
12190,12168,12148,12129,12113,12098,12085,12073,
12064,12056,12049,12044,12041,12040,12040,12042,
12046,12051,12058,12066,12076,12088,12101,12116,
12133,12151,12171,12192,12215,12240,12266,12294,
12323,12354,12386,12420,12456,12493,12532,12572,
12614,12657,12702,12749,12797,12846,12897,12950,
13004,13060,13117,13176,13237,13299,13362,13427,
13494,13562,13632,13703,13776,13850,13926,14003,
14082,14162,14244,14327,14412,14499,14587,14676,
14767,14860,14954,15049,15146,15245,15345,15446,
15549,15654,15760,15867,15976,16086,16198,16311,
16426,16543,16660,16779,16900,17022,17146,17270,
17397,17525,17654,17784,17916,18050,18184,18320,
18458,18597,18737,18878,19021,19165,19311,19458,
19606,19755,19906,20058,20211,20366,20521,20678,
20836,20996,21156,21318,21481,21645,21810,21976,
22144,22312,22482,22653,22824,22997,23171,23346,
23521,23698,23876,24055,24234,24415,24596,24778,
24962,25146,25330,25516,25702,25890,26077,26266,
26455,26645,26836,27028,27220,27412,27605,27799,
27994,28188,28384,28580,28776,28973,29170,29368,
29566,29764,29963,30162,30361,30560,30760,30960,
31160,31361,31561,31762,31963,32164,32365,32566,
32767,32968,33169,33370,33571,33772,33973,34173,
34374,34574,34774,34974,35173,35372,35571,35770,
35968,36166,36364,36561,36758,36954,37150,37346,
37540,37735,37929,38122,38314,38506,38698,38889,
39079,39268,39457,39644,39832,40018,40204,40388,
40572,40756,40938,41119,41300,41479,41658,41836,
42013,42188,42363,42537,42710,42881,43052,43222,
43390,43558,43724,43889,44053,44216,44378,44538,
44698,44856,45013,45168,45323,45476,45628,45779,
45928,46076,46223,46369,46513,46656,46797,46937,
47076,47214,47350,47484,47618,47750,47880,48009,
48137,48264,48388,48512,48634,48755,48874,48991,
49108,49223,49336,49448,49558,49667,49774,49880,
49985,50088,50189,50289,50388,50485,50580,50674,
50767,50858,50947,51035,51122,51207,51290,51372,
51452,51531,51608,51684,51758,51831,51902,51972,
52040,52107,52172,52235,52297,52358,52417,52474,
52530,52584,52637,52688,52737,52785,52832,52877,
52920,52962,53002,53041,53078,53114,53148,53180,
53211,53240,53268,53294,53319,53342,53363,53383,
53401,53418,53433,53446,53458,53468,53476,53483,
53488,53492,53494,53494,53493,53490,53485,53478,
53470,53461,53449,53436,53421,53405,53386,53366,
53344,53321,53296,53268,53240,53209,53176,53142,
53106,53068,53029,52987,52943,52898,52851,52802,
52751,52698,52643,52586,52527,52467,52404,52339,
52272,52204,52133,52060,51985,51908,51829,51748,
51664,51579,51491,51401,51309,51215,51119,51020,
50919,50816,50710,50602,50492,50380,50265,50148,
50028,49906,49782,49655,49526,49394,49260,49123,
48984,48842,48698,48551,48402,48250,48095,47938,
47778,47616,47451,47283,47112,46939,46763,46584,
46403,46219,46032,45842,45649,45454,45256,45055,
44851,44645,44435,44223,44007,43789,43568,43345,
43118,42888,42656,42420,42182,41941,41697,41450,
41200,40947,40692,40433,40172,39908,39640,39370,
39098,38822,38544,38262,37978,37691,37402,37109,
36814,36516,36216,35913,35607,35298,34987,34674,
34358,34039,33718,33394,33068,32740,32409,32076,
31741,31403,31064,30722,30378,30032,29685,29335,
28983,28630,28274,27918,27559,27199,26837,26474,
26109,25744,25376,25008,24639,24268,23897,23525,
23152,22778,22404,22029,21653,21277,20901,20525,
20149,19773,19396,19020,18645,18269,17894,17520,
17147,16774,16402,16032,15662,15294,14927,14561,
14197,13835,13475,13117,12760,12406,12055,11705,
11359,11015,10674,10335,10000, 9669, 9340, 9015,
 8694, 8376, 8062, 7752, 7446, 7145, 6848, 6555,
 6268, 5984, 5706, 5433, 5165, 4903, 4645, 4394,
 4148, 3908, 3674, 3446, 3224, 3008, 2799, 2597,
 2401, 2212, 2030, 1855, 1688, 1527, 1374, 1229,
 1091,  960,  838,  724,  617,  519,  429,  347,
  274,  209,  153,  105,   66,   36,   15,    3,
    0,    6,   21,   46,   79,  122,  175,  236,
  308,  388,  479,  578,  688,  807,  935, 1074,
 1221, 1379, 1546, 1723, 1909, 2106, 2311, 2527,
 2751, 2986, 3230, 3483, 3746, 4018, 4300, 4591,
 4891, 5200, 5518, 5846, 6182, 6527, 6881, 7244,
 7615, 7995, 8383, 8779, 9184, 9596,10017,10445,
10882,11325,11776,12235,12700,13173,13652,14139,
14631,15130,15636,16147,16664,17187,17716,18250,
18789,19333,19882,20435,20993,21555,22121,22691,
23265,23842,24423,25006,25592,26181,26772,27365,
27960,28557,29156,29756,30357,30958,31561,32164};

const uint16_t saw_table[ARR_SIZE] = {
0x0000,0x0040,0x0080,0x00C0,0x0100,0x0140,0x0180,
0x01C0,0x0200,0x0240,0x0280,0x02C0,0x0300,0x0340,
0x0380,0x03C0,0x0400,0x0440,0x0480,0x04C0,0x0500,
0x0540,0x0580,0x05C0,0x0600,0x0640,0x0680,0x06C0,
0x0700,0x0740,0x0780,0x07C0,0x0800,0x0840,0x0880,
0x08C0,0x0900,0x0940,0x0980,0x09C0,0x0A00,0x0A40,
0x0A80,0x0AC0,0x0B00,0x0B40,0x0B80,0x0BC0,0x0C00,
0x0C40,0x0C80,0x0CC0,0x0D00,0x0D40,0x0D80,0x0DC0,
0x0E00,0x0E40,0x0E80,0x0EC0,0x0F00,0x0F40,0x0F80,
0x0FC0,0x1000,0x1040,0x1080,0x10C0,0x1100,0x1140,
0x1180,0x11C0,0x1200,0x1240,0x1280,0x12C0,0x1300,
0x1340,0x1380,0x13C0,0x1400,0x1440,0x1480,0x14C0,
0x1500,0x1540,0x1580,0x15C0,0x1600,0x1640,0x1680,
0x16C0,0x1700,0x1740,0x1780,0x17C0,0x1800,0x1840,
0x1880,0x18C0,0x1900,0x1940,0x1980,0x19C0,0x1A00,
0x1A40,0x1A80,0x1AC0,0x1B00,0x1B40,0x1B80,0x1BC0,
0x1C00,0x1C40,0x1C80,0x1CC0,0x1D00,0x1D40,0x1D80,
0x1DC0,0x1E00,0x1E40,0x1E80,0x1EC0,0x1F00,0x1F40,
0x1F80,0x1FC0,0x2000,0x2040,0x2080,0x20C0,0x2100,
0x2140,0x2180,0x21C0,0x2200,0x2240,0x2280,0x22C0,
0x2300,0x2340,0x2380,0x23C0,0x2400,0x2440,0x2480,
0x24C0,0x2500,0x2540,0x2580,0x25C0,0x2600,0x2640,
0x2680,0x26C0,0x2700,0x2740,0x2780,0x27C0,0x2800,
0x2840,0x2880,0x28C0,0x2900,0x2940,0x2980,0x29C0,
0x2A00,0x2A40,0x2A80,0x2AC0,0x2B00,0x2B40,0x2B80,
0x2BC0,0x2C00,0x2C40,0x2C80,0x2CC0,0x2D00,0x2D40,
0x2D80,0x2DC0,0x2E00,0x2E40,0x2E80,0x2EC0,0x2F00,
0x2F40,0x2F80,0x2FC0,0x3000,0x3040,0x3080,0x30C0,
0x3100,0x3140,0x3180,0x31C0,0x3200,0x3240,0x3280,
0x32C0,0x3300,0x3340,0x3380,0x33C0,0x3400,0x3440,
0x3480,0x34C0,0x3500,0x3540,0x3580,0x35C0,0x3600,
0x3640,0x3680,0x36C0,0x3700,0x3740,0x3780,0x37C0,
0x3800,0x3840,0x3880,0x38C0,0x3900,0x3940,0x3980,
0x39C0,0x3A00,0x3A40,0x3A80,0x3AC0,0x3B00,0x3B40,
0x3B80,0x3BC0,0x3C00,0x3C40,0x3C80,0x3CC0,0x3D00,
0x3D40,0x3D80,0x3DC0,0x3E00,0x3E40,0x3E80,0x3EC0,
0x3F00,0x3F40,0x3F80,0x3FC0,0x4000,0x403F,0x407F,
0x40BF,0x40FF,0x413F,0x417F,0x41BF,0x41FF,0x423F,
0x427F,0x42BF,0x42FF,0x433F,0x437F,0x43BF,0x43FF,
0x443F,0x447F,0x44BF,0x44FF,0x453F,0x457F,0x45BF,
0x45FF,0x463F,0x467F,0x46BF,0x46FF,0x473F,0x477F,
0x47BF,0x47FF,0x483F,0x487F,0x48BF,0x48FF,0x493F,
0x497F,0x49BF,0x49FF,0x4A3F,0x4A7F,0x4ABF,0x4AFF,
0x4B3F,0x4B7F,0x4BBF,0x4BFF,0x4C3F,0x4C7F,0x4CBF,
0x4CFF,0x4D3F,0x4D7F,0x4DBF,0x4DFF,0x4E3F,0x4E7F,
0x4EBF,0x4EFF,0x4F3F,0x4F7F,0x4FBF,0x4FFF,0x503F,
0x507F,0x50BF,0x50FF,0x513F,0x517F,0x51BF,0x51FF,
0x523F,0x527F,0x52BF,0x52FF,0x533F,0x537F,0x53BF,
0x53FF,0x543F,0x547F,0x54BF,0x54FF,0x553F,0x557F,
0x55BF,0x55FF,0x563F,0x567F,0x56BF,0x56FF,0x573F,
0x577F,0x57BF,0x57FF,0x583F,0x587F,0x58BF,0x58FF,
0x593F,0x597F,0x59BF,0x59FF,0x5A3F,0x5A7F,0x5ABF,
0x5AFF,0x5B3F,0x5B7F,0x5BBF,0x5BFF,0x5C3F,0x5C7F,
0x5CBF,0x5CFF,0x5D3F,0x5D7F,0x5DBF,0x5DFF,0x5E3F,
0x5E7F,0x5EBF,0x5EFF,0x5F3F,0x5F7F,0x5FBF,0x5FFF,
0x603F,0x607F,0x60BF,0x60FF,0x613F,0x617F,0x61BF,
0x61FF,0x623F,0x627F,0x62BF,0x62FF,0x633F,0x637F,
0x63BF,0x63FF,0x643F,0x647F,0x64BF,0x64FF,0x653F,
0x657F,0x65BF,0x65FF,0x663F,0x667F,0x66BF,0x66FF,
0x673F,0x677F,0x67BF,0x67FF,0x683F,0x687F,0x68BF,
0x68FF,0x693F,0x697F,0x69BF,0x69FF,0x6A3F,0x6A7F,
0x6ABF,0x6AFF,0x6B3F,0x6B7F,0x6BBF,0x6BFF,0x6C3F,
0x6C7F,0x6CBF,0x6CFF,0x6D3F,0x6D7F,0x6DBF,0x6DFF,
0x6E3F,0x6E7F,0x6EBF,0x6EFF,0x6F3F,0x6F7F,0x6FBF,
0x6FFF,0x703F,0x707F,0x70BF,0x70FF,0x713F,0x717F,
0x71BF,0x71FF,0x723F,0x727F,0x72BF,0x72FF,0x733F,
0x737F,0x73BF,0x73FF,0x743F,0x747F,0x74BF,0x74FF,
0x753F,0x757F,0x75BF,0x75FF,0x763F,0x767F,0x76BF,
0x76FF,0x773F,0x777F,0x77BF,0x77FF,0x783F,0x787F,
0x78BF,0x78FF,0x793F,0x797F,0x79BF,0x79FF,0x7A3F,
0x7A7F,0x7ABF,0x7AFF,0x7B3F,0x7B7F,0x7BBF,0x7BFF,
0x7C3F,0x7C7F,0x7CBF,0x7CFF,0x7D3F,0x7D7F,0x7DBF,
0x7DFF,0x7E3F,0x7E7F,0x7EBF,0x7EFF,0x7F3F,0x7F7F,
0x7FBF,0x7FFF,0x803F,0x807F,0x80BF,0x80FF,0x813F,
0x817F,0x81BF,0x81FF,0x823F,0x827F,0x82BF,0x82FF,
0x833F,0x837F,0x83BF,0x83FF,0x843F,0x847F,0x84BF,
0x84FF,0x853F,0x857F,0x85BF,0x85FF,0x863F,0x867F,
0x86BF,0x86FF,0x873F,0x877F,0x87BF,0x87FF,0x883F,
0x887F,0x88BF,0x88FF,0x893F,0x897F,0x89BF,0x89FF,
0x8A3F,0x8A7F,0x8ABF,0x8AFF,0x8B3F,0x8B7F,0x8BBF,
0x8BFF,0x8C3F,0x8C7F,0x8CBF,0x8CFF,0x8D3F,0x8D7F,
0x8DBF,0x8DFF,0x8E3F,0x8E7F,0x8EBF,0x8EFF,0x8F3F,
0x8F7F,0x8FBF,0x8FFF,0x903F,0x907F,0x90BF,0x90FF,
0x913F,0x917F,0x91BF,0x91FF,0x923F,0x927F,0x92BF,
0x92FF,0x933F,0x937F,0x93BF,0x93FF,0x943F,0x947F,
0x94BF,0x94FF,0x953F,0x957F,0x95BF,0x95FF,0x963F,
0x967F,0x96BF,0x96FF,0x973F,0x977F,0x97BF,0x97FF,
0x983F,0x987F,0x98BF,0x98FF,0x993F,0x997F,0x99BF,
0x99FF,0x9A3F,0x9A7F,0x9ABF,0x9AFF,0x9B3F,0x9B7F,
0x9BBF,0x9BFF,0x9C3F,0x9C7F,0x9CBF,0x9CFF,0x9D3F,
0x9D7F,0x9DBF,0x9DFF,0x9E3F,0x9E7F,0x9EBF,0x9EFF,
0x9F3F,0x9F7F,0x9FBF,0x9FFF,0xA03F,0xA07F,0xA0BF,
0xA0FF,0xA13F,0xA17F,0xA1BF,0xA1FF,0xA23F,0xA27F,
0xA2BF,0xA2FF,0xA33F,0xA37F,0xA3BF,0xA3FF,0xA43F,
0xA47F,0xA4BF,0xA4FF,0xA53F,0xA57F,0xA5BF,0xA5FF,
0xA63F,0xA67F,0xA6BF,0xA6FF,0xA73F,0xA77F,0xA7BF,
0xA7FF,0xA83F,0xA87F,0xA8BF,0xA8FF,0xA93F,0xA97F,
0xA9BF,0xA9FF,0xAA3F,0xAA7F,0xAABF,0xAAFF,0xAB3F,
0xAB7F,0xABBF,0xABFF,0xAC3F,0xAC7F,0xACBF,0xACFF,
0xAD3F,0xAD7F,0xADBF,0xADFF,0xAE3F,0xAE7F,0xAEBF,
0xAEFF,0xAF3F,0xAF7F,0xAFBF,0xAFFF,0xB03F,0xB07F,
0xB0BF,0xB0FF,0xB13F,0xB17F,0xB1BF,0xB1FF,0xB23F,
0xB27F,0xB2BF,0xB2FF,0xB33F,0xB37F,0xB3BF,0xB3FF,
0xB43F,0xB47F,0xB4BF,0xB4FF,0xB53F,0xB57F,0xB5BF,
0xB5FF,0xB63F,0xB67F,0xB6BF,0xB6FF,0xB73F,0xB77F,
0xB7BF,0xB7FF,0xB83F,0xB87F,0xB8BF,0xB8FF,0xB93F,
0xB97F,0xB9BF,0xB9FF,0xBA3F,0xBA7F,0xBABF,0xBAFF,
0xBB3F,0xBB7F,0xBBBF,0xBBFF,0xBC3F,0xBC7F,0xBCBF,
0xBCFF,0xBD3F,0xBD7F,0xBDBF,0xBDFF,0xBE3F,0xBE7F,
0xBEBF,0xBEFF,0xBF3F,0xBF7F,0xBFBF,0xBFFE,0xC03E,
0xC07E,0xC0BE,0xC0FE,0xC13E,0xC17E,0xC1BE,0xC1FE,
0xC23E,0xC27E,0xC2BE,0xC2FE,0xC33E,0xC37E,0xC3BE,
0xC3FE,0xC43E,0xC47E,0xC4BE,0xC4FE,0xC53E,0xC57E,
0xC5BE,0xC5FE,0xC63E,0xC67E,0xC6BE,0xC6FE,0xC73E,
0xC77E,0xC7BE,0xC7FE,0xC83E,0xC87E,0xC8BE,0xC8FE,
0xC93E,0xC97E,0xC9BE,0xC9FE,0xCA3E,0xCA7E,0xCABE,
0xCAFE,0xCB3E,0xCB7E,0xCBBE,0xCBFE,0xCC3E,0xCC7E,
0xCCBE,0xCCFE,0xCD3E,0xCD7E,0xCDBE,0xCDFE,0xCE3E,
0xCE7E,0xCEBE,0xCEFE,0xCF3E,0xCF7E,0xCFBE,0xCFFE,
0xD03E,0xD07E,0xD0BE,0xD0FE,0xD13E,0xD17E,0xD1BE,
0xD1FE,0xD23E,0xD27E,0xD2BE,0xD2FE,0xD33E,0xD37E,
0xD3BE,0xD3FE,0xD43E,0xD47E,0xD4BE,0xD4FE,0xD53E,
0xD57E,0xD5BE,0xD5FE,0xD63E,0xD67E,0xD6BE,0xD6FE,
0xD73E,0xD77E,0xD7BE,0xD7FE,0xD83E,0xD87E,0xD8BE,
0xD8FE,0xD93E,0xD97E,0xD9BE,0xD9FE,0xDA3E,0xDA7E,
0xDABE,0xDAFE,0xDB3E,0xDB7E,0xDBBE,0xDBFE,0xDC3E,
0xDC7E,0xDCBE,0xDCFE,0xDD3E,0xDD7E,0xDDBE,0xDDFE,
0xDE3E,0xDE7E,0xDEBE,0xDEFE,0xDF3E,0xDF7E,0xDFBE,
0xDFFE,0xE03E,0xE07E,0xE0BE,0xE0FE,0xE13E,0xE17E,
0xE1BE,0xE1FE,0xE23E,0xE27E,0xE2BE,0xE2FE,0xE33E,
0xE37E,0xE3BE,0xE3FE,0xE43E,0xE47E,0xE4BE,0xE4FE,
0xE53E,0xE57E,0xE5BE,0xE5FE,0xE63E,0xE67E,0xE6BE,
0xE6FE,0xE73E,0xE77E,0xE7BE,0xE7FE,0xE83E,0xE87E,
0xE8BE,0xE8FE,0xE93E,0xE97E,0xE9BE,0xE9FE,0xEA3E,
0xEA7E,0xEABE,0xEAFE,0xEB3E,0xEB7E,0xEBBE,0xEBFE,
0xEC3E,0xEC7E,0xECBE,0xECFE,0xED3E,0xED7E,0xEDBE,
0xEDFE,0xEE3E,0xEE7E,0xEEBE,0xEEFE,0xEF3E,0xEF7E,
0xEFBE,0xEFFE,0xF03E,0xF07E,0xF0BE,0xF0FE,0xF13E,
0xF17E,0xF1BE,0xF1FE,0xF23E,0xF27E,0xF2BE,0xF2FE,
0xF33E,0xF37E,0xF3BE,0xF3FE,0xF43E,0xF47E,0xF4BE,
0xF4FE,0xF53E,0xF57E,0xF5BE,0xF5FE,0xF63E,0xF67E,
0xF6BE,0xF6FE,0xF73E,0xF77E,0xF7BE,0xF7FE,0xF83E,
0xF87E,0xF8BE,0xF8FE,0xF93E,0xF97E,0xF9BE,0xF9FE,
0xFA3E,0xFA7E,0xFABE,0xFAFE,0xFB3E,0xFB7E,0xFBBE,
0xFBFE,0xFC3E,0xFC7E,0xFCBE,0xFCFE,0xFD3E,0xFD7E,
0xFDBE,0xFDFE,0xFE3E,0xFE7E,0xFEBE,0xFEFE,0xFF3E,
0xFF7E,0xFFBE};

const uint16_t* arrayOfSounds[] = {sine_table, saw_table, wave1_table};
const uint16_t* selectedArray;

const uint16_t frequencies [12] = {
	C_NOTE, CIS_NOTE, D_NOTE, DIS_NOTE, E_NOTE, F_NOTE, FIS_NOTE, G_NOTE, GIS_NOTE, A_NOTE, AIS_NOTE, H_NOTE
};

/* USER CODE END PM */

CRC_HandleTypeDef hcrc;

DMA2D_HandleTypeDef hdma2d;

JPEG_HandleTypeDef hjpeg;
MDMA_HandleTypeDef hmdma_jpeg_infifo_th;
MDMA_HandleTypeDef hmdma_jpeg_outfifo_th;

LTDC_HandleTypeDef hltdc;

QSPI_HandleTypeDef hqspi;

SPI_HandleTypeDef hspi4;

TIM_HandleTypeDef htim1;
TIM_HandleTypeDef htim5;

SDRAM_HandleTypeDef hsdram2;

/* Definitions for defaultTask */
osThreadId_t defaultTaskHandle;
const osThreadAttr_t defaultTask_attributes = {
  .name = "defaultTask",
  .stack_size = 128 * 4,
  .priority = (osPriority_t) osPriorityNormal,
};
/* Definitions for GUITask */
osThreadId_t GUITaskHandle;
const osThreadAttr_t GUITask_attributes = {
  .name = "GUITask",
  .stack_size = 8192 * 4,
  .priority = (osPriority_t) osPriorityNormal,
};
/* Definitions for playNoteTask */
osThreadId_t playNoteTaskHandle;
const osThreadAttr_t playNoteTask_attributes = {
  .name = "playNoteTask",
  .stack_size = 128 * 4,
  .priority = (osPriority_t) osPriorityLow,
};
/* Definitions for noteQueue */
osMessageQueueId_t noteQueueHandle;
const osMessageQueueAttr_t noteQueue_attributes = {
  .name = "noteQueue"
};
/* USER CODE BEGIN PV */
osMessageQueueId_t stateQueueHandle;
const osMessageQueueAttr_t stateQueue_attributes = {
  .name = "stateQueue"
};
osMessageQueueId_t soundQueueHandle;
const osMessageQueueAttr_t soundQueue_attributes = {
  .name = "soundQueue"
};
/* USER CODE END PV */

void SystemClock_Config(void);
static void MPU_Config(void);
static void MX_GPIO_Init(void);
static void MX_MDMA_Init(void);
static void MX_LTDC_Init(void);
static void MX_DMA2D_Init(void);
static void MX_QUADSPI_Init(void);
static void MX_FMC_Init(void);
static void MX_JPEG_Init(void);
static void MX_CRC_Init(void);
static void MX_SPI4_Init(void);
static void MX_TIM1_Init(void);
static void MX_TIM5_Init(void);
void StartDefaultTask(void *argument);
extern void TouchGFX_Task(void *argument);
void playNoteTaskFunction(void *argument);

int main(void)
{

  /* MPU Configuration--------------------------------------------------------*/
  MPU_Config();

  /* Enable the CPU Cache */

  /* Enable I-Cache---------------------------------------------------------*/
  SCB_EnableICache();

  /* Enable D-Cache---------------------------------------------------------*/
  SCB_EnableDCache();

  /* MCU Configuration--------------------------------------------------------*/

  /* Reset of all peripherals, Initializes the Flash interface and the Systick. */
  HAL_Init();

  /* Configure the system clock */
  SystemClock_Config();

  /* USER CODE BEGIN SysInit */
  /* Explicit enabling interrupt to support debugging in STM32CubeIDE when using external flash loader */
  __enable_irq();
  selectedArray = arrayOfSounds[0];
  /* USER CODE END SysInit */

  /* Initialize all configured peripherals */
  MX_GPIO_Init();
  MX_MDMA_Init();
  MX_LTDC_Init();
  MX_DMA2D_Init();
  MX_FMC_Init();
  MX_LIBJPEG_Init();
  MX_JPEG_Init();
  MX_CRC_Init();
  MX_SPI4_Init();
  MX_TIM1_Init();
  MX_TIM5_Init();
  MX_TouchGFX_Init();
  /* Call PreOsInit function */
  MX_TouchGFX_PreOSInit();

  /* Init scheduler */
  osKernelInitialize();

  /* Create the queue(s) */
  /* creation of noteQueue */
  noteQueueHandle = osMessageQueueNew (16, sizeof(uint8_t), &noteQueue_attributes);
  stateQueueHandle = osMessageQueueNew (16, sizeof(uint8_t), &stateQueue_attributes);
  soundQueueHandle = osMessageQueueNew (16, sizeof(uint8_t), &soundQueue_attributes);

  /* Create the thread(s) */
  /* creation of defaultTask */
  defaultTaskHandle = osThreadNew(StartDefaultTask, NULL, &defaultTask_attributes);

  /* creation of GUITask */
  GUITaskHandle = osThreadNew(TouchGFX_Task, NULL, &GUITask_attributes);

  /* creation of playNoteTask */
  playNoteTaskHandle = osThreadNew(playNoteTaskFunction, NULL, &playNoteTask_attributes);

  /* Start scheduler */
  osKernelStart();

  /* We should never get here as control is now taken by the scheduler */

  /* Infinite loop */
  while (1)
  {

  }
}

void SystemClock_Config(void)
{
  RCC_OscInitTypeDef RCC_OscInitStruct = {0};
  RCC_ClkInitTypeDef RCC_ClkInitStruct = {0};

  /** Supply configuration update enable
  */
  HAL_PWREx_ConfigSupply(PWR_LDO_SUPPLY);

  /** Configure the main internal regulator output voltage
  */
  __HAL_PWR_VOLTAGESCALING_CONFIG(PWR_REGULATOR_VOLTAGE_SCALE1);

  while(!__HAL_PWR_GET_FLAG(PWR_FLAG_VOSRDY)) {}

  __HAL_RCC_SYSCFG_CLK_ENABLE();
  __HAL_PWR_VOLTAGESCALING_CONFIG(PWR_REGULATOR_VOLTAGE_SCALE0);

  while(!__HAL_PWR_GET_FLAG(PWR_FLAG_VOSRDY)) {}

  /** Initializes the RCC Oscillators according to the specified parameters
  * in the RCC_OscInitTypeDef structure.
  */
  RCC_OscInitStruct.OscillatorType = RCC_OSCILLATORTYPE_HSE;
  RCC_OscInitStruct.HSEState = RCC_HSE_ON;
  RCC_OscInitStruct.PLL.PLLState = RCC_PLL_ON;
  RCC_OscInitStruct.PLL.PLLSource = RCC_PLLSOURCE_HSE;
  RCC_OscInitStruct.PLL.PLLM = 5;
  RCC_OscInitStruct.PLL.PLLN = 192;
  RCC_OscInitStruct.PLL.PLLP = 2;
  RCC_OscInitStruct.PLL.PLLQ = 4;
  RCC_OscInitStruct.PLL.PLLR = 2;
  RCC_OscInitStruct.PLL.PLLRGE = RCC_PLL1VCIRANGE_2;
  RCC_OscInitStruct.PLL.PLLVCOSEL = RCC_PLL1VCOWIDE;
  RCC_OscInitStruct.PLL.PLLFRACN = 0;
  if (HAL_RCC_OscConfig(&RCC_OscInitStruct) != HAL_OK)
  {
    Error_Handler();
  }

  /** Initializes the CPU, AHB and APB buses clocks
  */
  RCC_ClkInitStruct.ClockType = RCC_CLOCKTYPE_HCLK|RCC_CLOCKTYPE_SYSCLK
                              |RCC_CLOCKTYPE_PCLK1|RCC_CLOCKTYPE_PCLK2
                              |RCC_CLOCKTYPE_D3PCLK1|RCC_CLOCKTYPE_D1PCLK1;
  RCC_ClkInitStruct.SYSCLKSource = RCC_SYSCLKSOURCE_PLLCLK;
  RCC_ClkInitStruct.SYSCLKDivider = RCC_SYSCLK_DIV1;
  RCC_ClkInitStruct.AHBCLKDivider = RCC_HCLK_DIV2;
  RCC_ClkInitStruct.APB3CLKDivider = RCC_APB3_DIV2;
  RCC_ClkInitStruct.APB1CLKDivider = RCC_APB1_DIV2;
  RCC_ClkInitStruct.APB2CLKDivider = RCC_APB2_DIV2;
  RCC_ClkInitStruct.APB4CLKDivider = RCC_APB4_DIV2;

  if (HAL_RCC_ClockConfig(&RCC_ClkInitStruct, FLASH_LATENCY_4) != HAL_OK)
  {
    Error_Handler();
  }
}

static void MX_CRC_Init(void)
{

  hcrc.Instance = CRC;
  hcrc.Init.DefaultPolynomialUse = DEFAULT_POLYNOMIAL_ENABLE;
  hcrc.Init.DefaultInitValueUse = DEFAULT_INIT_VALUE_ENABLE;
  hcrc.Init.InputDataInversionMode = CRC_INPUTDATA_INVERSION_NONE;
  hcrc.Init.OutputDataInversionMode = CRC_OUTPUTDATA_INVERSION_DISABLE;
  hcrc.InputDataFormat = CRC_INPUTDATA_FORMAT_BYTES;
  if (HAL_CRC_Init(&hcrc) != HAL_OK)
  {
    Error_Handler();
  }

}

static void MX_DMA2D_Init(void)
{

  hdma2d.Instance = DMA2D;
  hdma2d.Init.Mode = DMA2D_M2M;
  hdma2d.Init.ColorMode = DMA2D_OUTPUT_RGB565;
  hdma2d.Init.OutputOffset = 0;
  hdma2d.LayerCfg[1].InputOffset = 0;
  hdma2d.LayerCfg[1].InputColorMode = DMA2D_INPUT_RGB565;
  hdma2d.LayerCfg[1].AlphaMode = DMA2D_NO_MODIF_ALPHA;
  hdma2d.LayerCfg[1].InputAlpha = 0;
  hdma2d.LayerCfg[1].AlphaInverted = DMA2D_REGULAR_ALPHA;
  hdma2d.LayerCfg[1].RedBlueSwap = DMA2D_RB_REGULAR;
  hdma2d.LayerCfg[1].ChromaSubSampling = DMA2D_NO_CSS;
  if (HAL_DMA2D_Init(&hdma2d) != HAL_OK)
  {
    Error_Handler();
  }
  if (HAL_DMA2D_ConfigLayer(&hdma2d, 1) != HAL_OK)
  {
    Error_Handler();
  }

}

static void MX_JPEG_Init(void)
{

  hjpeg.Instance = JPEG;
  if (HAL_JPEG_Init(&hjpeg) != HAL_OK)
  {
    Error_Handler();
  }

}

static void MX_LTDC_Init(void)
{

  LTDC_LayerCfgTypeDef pLayerCfg = {0};

  hltdc.Instance = LTDC;
  hltdc.Init.HSPolarity = LTDC_HSPOLARITY_AL;
  hltdc.Init.VSPolarity = LTDC_VSPOLARITY_AL;
  hltdc.Init.DEPolarity = LTDC_DEPOLARITY_AL;
  hltdc.Init.PCPolarity = LTDC_PCPOLARITY_IPC;
  hltdc.Init.HorizontalSync = 39;
  hltdc.Init.VerticalSync = 8;
  hltdc.Init.AccumulatedHBP = 42;
  hltdc.Init.AccumulatedVBP = 11;
  hltdc.Init.AccumulatedActiveW = 522;
  hltdc.Init.AccumulatedActiveH = 283;
  hltdc.Init.TotalWidth = 528;
  hltdc.Init.TotalHeigh = 285;
  hltdc.Init.Backcolor.Blue = 0;
  hltdc.Init.Backcolor.Green = 0;
  hltdc.Init.Backcolor.Red = 0;
  if (HAL_LTDC_Init(&hltdc) != HAL_OK)
  {
    Error_Handler();
  }
  pLayerCfg.WindowX0 = 0;
  pLayerCfg.WindowX1 = 480;
  pLayerCfg.WindowY0 = 0;
  pLayerCfg.WindowY1 = 272;
  pLayerCfg.PixelFormat = LTDC_PIXEL_FORMAT_RGB565;
  pLayerCfg.Alpha = 255;
  pLayerCfg.Alpha0 = 0;
  pLayerCfg.BlendingFactor1 = LTDC_BLENDING_FACTOR1_CA;
  pLayerCfg.BlendingFactor2 = LTDC_BLENDING_FACTOR2_CA;
  pLayerCfg.FBStartAdress = 0;
  pLayerCfg.ImageWidth = 480;
  pLayerCfg.ImageHeight = 272;
  pLayerCfg.Backcolor.Blue = 0;
  pLayerCfg.Backcolor.Green = 0;
  pLayerCfg.Backcolor.Red = 0;
  if (HAL_LTDC_ConfigLayer(&hltdc, &pLayerCfg, 0) != HAL_OK)
  {
    Error_Handler();
  }

}

static void MX_QUADSPI_Init(void)
{

  /* USER CODE BEGIN QUADSPI_Init 0 */
  BSP_QSPI_Init_t qspi_initParams ;
  /* USER CODE END QUADSPI_Init 0 */

  /* QUADSPI parameter configuration*/
  hqspi.Instance = QUADSPI;
  hqspi.Init.ClockPrescaler = 3;
  hqspi.Init.FifoThreshold = 1;
  hqspi.Init.SampleShifting = QSPI_SAMPLE_SHIFTING_NONE;
  hqspi.Init.FlashSize = 26;
  hqspi.Init.ChipSelectHighTime = QSPI_CS_HIGH_TIME_4_CYCLE;
  hqspi.Init.ClockMode = QSPI_CLOCK_MODE_0;
  hqspi.Init.DualFlash = QSPI_DUALFLASH_ENABLE;
  if (HAL_QSPI_Init(&hqspi) != HAL_OK)
  {
    Error_Handler();
  }
  /* USER CODE BEGIN QUADSPI_Init 2 */
  qspi_initParams.InterfaceMode = MT25TL01G_QPI_MODE;
  qspi_initParams.TransferRate  = MT25TL01G_DTR_TRANSFER ;
  qspi_initParams.DualFlashMode = MT25TL01G_DUALFLASH_ENABLE;
  BSP_QSPI_DeInit(0);
  if (BSP_QSPI_Init(0, &qspi_initParams) != BSP_ERROR_NONE)
  {
    Error_Handler( );
  }
  if(BSP_QSPI_EnableMemoryMappedMode(0) != BSP_ERROR_NONE)
  {
    Error_Handler( );
  }
  /* USER CODE END QUADSPI_Init 2 */

}

static void MX_SPI4_Init(void)
{

  /* SPI4 parameter configuration*/
  hspi4.Instance = SPI4;
  hspi4.Init.Mode = SPI_MODE_MASTER;
  hspi4.Init.Direction = SPI_DIRECTION_2LINES_TXONLY;
  hspi4.Init.DataSize = SPI_DATASIZE_4BIT;
  hspi4.Init.CLKPolarity = SPI_POLARITY_LOW;
  hspi4.Init.CLKPhase = SPI_PHASE_1EDGE;
  hspi4.Init.NSS = SPI_NSS_SOFT;
  hspi4.Init.BaudRatePrescaler = SPI_BAUDRATEPRESCALER_2;
  hspi4.Init.FirstBit = SPI_FIRSTBIT_MSB;
  hspi4.Init.TIMode = SPI_TIMODE_DISABLE;
  hspi4.Init.CRCCalculation = SPI_CRCCALCULATION_DISABLE;
  hspi4.Init.CRCPolynomial = 0x0;
  hspi4.Init.NSSPMode = SPI_NSS_PULSE_ENABLE;
  hspi4.Init.NSSPolarity = SPI_NSS_POLARITY_LOW;
  hspi4.Init.FifoThreshold = SPI_FIFO_THRESHOLD_01DATA;
  hspi4.Init.TxCRCInitializationPattern = SPI_CRC_INITIALIZATION_ALL_ZERO_PATTERN;
  hspi4.Init.RxCRCInitializationPattern = SPI_CRC_INITIALIZATION_ALL_ZERO_PATTERN;
  hspi4.Init.MasterSSIdleness = SPI_MASTER_SS_IDLENESS_00CYCLE;
  hspi4.Init.MasterInterDataIdleness = SPI_MASTER_INTERDATA_IDLENESS_00CYCLE;
  hspi4.Init.MasterReceiverAutoSusp = SPI_MASTER_RX_AUTOSUSP_DISABLE;
  hspi4.Init.MasterKeepIOState = SPI_MASTER_KEEP_IO_STATE_DISABLE;
  hspi4.Init.IOSwap = SPI_IO_SWAP_DISABLE;
  if (HAL_SPI_Init(&hspi4) != HAL_OK)
  {
    Error_Handler();
  }

}

static void MX_TIM1_Init(void)
{

  TIM_ClockConfigTypeDef sClockSourceConfig = {0};
  TIM_MasterConfigTypeDef sMasterConfig = {0};

  htim1.Instance = TIM1;
  htim1.Init.Prescaler = 8;
  htim1.Init.CounterMode = TIM_COUNTERMODE_UP;
  htim1.Init.Period = 1000000;
  htim1.Init.ClockDivision = TIM_CLOCKDIVISION_DIV1;
  htim1.Init.RepetitionCounter = 0;
  htim1.Init.AutoReloadPreload = TIM_AUTORELOAD_PRELOAD_DISABLE;
  if (HAL_TIM_Base_Init(&htim1) != HAL_OK)
  {
    Error_Handler();
  }
  sClockSourceConfig.ClockSource = TIM_CLOCKSOURCE_INTERNAL;
  if (HAL_TIM_ConfigClockSource(&htim1, &sClockSourceConfig) != HAL_OK)
  {
    Error_Handler();
  }
  sMasterConfig.MasterOutputTrigger = TIM_TRGO_RESET;
  sMasterConfig.MasterOutputTrigger2 = TIM_TRGO2_RESET;
  sMasterConfig.MasterSlaveMode = TIM_MASTERSLAVEMODE_DISABLE;
  if (HAL_TIMEx_MasterConfigSynchronization(&htim1, &sMasterConfig) != HAL_OK)
  {
    Error_Handler();
  }
  /* USER CODE BEGIN TIM1_Init 2 */
  HAL_TIM_Base_Start(&htim1);
  /* USER CODE END TIM1_Init 2 */

}

static void MX_TIM5_Init(void)
{

  TIM_ClockConfigTypeDef sClockSourceConfig = {0};

  htim5.Instance = TIM5;
  htim5.Init.Prescaler = 3;
  htim5.Init.CounterMode = TIM_COUNTERMODE_UP;
  htim5.Init.Period = 3000;
  htim5.Init.ClockDivision = TIM_CLOCKDIVISION_DIV1;
  htim5.Init.AutoReloadPreload = TIM_AUTORELOAD_PRELOAD_ENABLE;
  if (HAL_TIM_Base_Init(&htim5) != HAL_OK)
  {
    Error_Handler();
  }
  /* USER CODE BEGIN TIM5_Init 2 */
  HAL_NVIC_SetPriority(TIM6_DAC_IRQn, 0, 0);
  HAL_NVIC_EnableIRQ(TIM6_DAC_IRQn);
  HAL_TIM_Base_Start_IT(&htim5);
  /* USER CODE END TIM5_Init 2 */

}

/**
  * Enable MDMA controller clock
  */
static void MX_MDMA_Init(void)
{

  /* MDMA controller clock enable */
  __HAL_RCC_MDMA_CLK_ENABLE();
  /* Local variables */

  /* MDMA interrupt initialization */
  /* MDMA_IRQn interrupt configuration */
  HAL_NVIC_SetPriority(MDMA_IRQn, 5, 0);
  HAL_NVIC_EnableIRQ(MDMA_IRQn);

}

/* FMC initialization function */
static void MX_FMC_Init(void)
{

  FMC_SDRAM_TimingTypeDef SdramTiming = {0};

  /** Perform the SDRAM2 memory initialization sequence
  */
  hsdram2.Instance = FMC_SDRAM_DEVICE;
  /* hsdram2.Init */
  hsdram2.Init.SDBank = FMC_SDRAM_BANK2;
  hsdram2.Init.ColumnBitsNumber = FMC_SDRAM_COLUMN_BITS_NUM_8;
  hsdram2.Init.RowBitsNumber = FMC_SDRAM_ROW_BITS_NUM_12;
  hsdram2.Init.MemoryDataWidth = FMC_SDRAM_MEM_BUS_WIDTH_16;
  hsdram2.Init.InternalBankNumber = FMC_SDRAM_INTERN_BANKS_NUM_4;
  hsdram2.Init.CASLatency = FMC_SDRAM_CAS_LATENCY_3;
  hsdram2.Init.WriteProtection = FMC_SDRAM_WRITE_PROTECTION_DISABLE;
  hsdram2.Init.SDClockPeriod = FMC_SDRAM_CLOCK_PERIOD_2;
  hsdram2.Init.ReadBurst = FMC_SDRAM_RBURST_ENABLE;
  hsdram2.Init.ReadPipeDelay = FMC_SDRAM_RPIPE_DELAY_0;
  /* SdramTiming */
  SdramTiming.LoadToActiveDelay = 2;
  SdramTiming.ExitSelfRefreshDelay = 7;
  SdramTiming.SelfRefreshTime = 4;
  SdramTiming.RowCycleDelay = 7;
  SdramTiming.WriteRecoveryTime = 5;
  SdramTiming.RPDelay = 2;
  SdramTiming.RCDDelay = 2;

  if (HAL_SDRAM_Init(&hsdram2, &SdramTiming) != HAL_OK)
  {
    Error_Handler( );
  }

  /* USER CODE BEGIN FMC_Init 2 */
  BSP_SDRAM_DeInit(0);
  if(BSP_SDRAM_Init(0) != BSP_ERROR_NONE)
  {
    Error_Handler( );
  }
  /* USER CODE END FMC_Init 2 */
}

static void MX_GPIO_Init(void)
{
  GPIO_InitTypeDef GPIO_InitStruct = {0};

  /* GPIO Ports Clock Enable */
  __HAL_RCC_GPIOK_CLK_ENABLE();
  __HAL_RCC_GPIOG_CLK_ENABLE();
  __HAL_RCC_GPIOI_CLK_ENABLE();
  __HAL_RCC_GPIOE_CLK_ENABLE();
  __HAL_RCC_GPIOB_CLK_ENABLE();
  __HAL_RCC_GPIOJ_CLK_ENABLE();
  __HAL_RCC_GPIOD_CLK_ENABLE();
  __HAL_RCC_GPIOF_CLK_ENABLE();
  __HAL_RCC_GPIOH_CLK_ENABLE();
  __HAL_RCC_GPIOA_CLK_ENABLE();

  /*Configure GPIO pin Output Level */
  HAL_GPIO_WritePin(GPIOB, FRAME_RATE_Pin|RENDER_TIME_Pin, GPIO_PIN_RESET);

  /*Configure GPIO pin Output Level */
  HAL_GPIO_WritePin(LCD_DE_GPIO_Port, LCD_DE_Pin, GPIO_PIN_RESET);

  /*Configure GPIO pin Output Level */
  HAL_GPIO_WritePin(GPIOI, GPIO_PIN_13, GPIO_PIN_RESET);

  /*Configure GPIO pin Output Level */
  HAL_GPIO_WritePin(VSYNC_FREQ_GPIO_Port, VSYNC_FREQ_Pin, GPIO_PIN_RESET);

  /*Configure GPIO pin Output Level */
  HAL_GPIO_WritePin(LCD_BL_CTRL_GPIO_Port, LCD_BL_CTRL_Pin, GPIO_PIN_SET);

  /*Configure GPIO pin Output Level */
  HAL_GPIO_WritePin(MCU_ACTIVE_GPIO_Port, MCU_ACTIVE_Pin, GPIO_PIN_RESET);

  /*Configure GPIO pins : FRAME_RATE_Pin RENDER_TIME_Pin */
  GPIO_InitStruct.Pin = FRAME_RATE_Pin|RENDER_TIME_Pin;
  GPIO_InitStruct.Mode = GPIO_MODE_OUTPUT_PP;
  GPIO_InitStruct.Pull = GPIO_NOPULL;
  GPIO_InitStruct.Speed = GPIO_SPEED_FREQ_VERY_HIGH;
  HAL_GPIO_Init(GPIOB, &GPIO_InitStruct);

  /*Configure GPIO pin : LCD_DE_Pin */
  GPIO_InitStruct.Pin = LCD_DE_Pin;
  GPIO_InitStruct.Mode = GPIO_MODE_OUTPUT_PP;
  GPIO_InitStruct.Pull = GPIO_NOPULL;
  GPIO_InitStruct.Speed = GPIO_SPEED_FREQ_LOW;
  HAL_GPIO_Init(LCD_DE_GPIO_Port, &GPIO_InitStruct);

  /*Configure GPIO pin : PI13 */
  GPIO_InitStruct.Pin = GPIO_PIN_13;
  GPIO_InitStruct.Mode = GPIO_MODE_OUTPUT_PP;
  GPIO_InitStruct.Pull = GPIO_NOPULL;
  GPIO_InitStruct.Speed = GPIO_SPEED_FREQ_LOW;
  HAL_GPIO_Init(GPIOI, &GPIO_InitStruct);

  /*Configure GPIO pin : VSYNC_FREQ_Pin */
  GPIO_InitStruct.Pin = VSYNC_FREQ_Pin;
  GPIO_InitStruct.Mode = GPIO_MODE_OUTPUT_PP;
  GPIO_InitStruct.Pull = GPIO_NOPULL;
  GPIO_InitStruct.Speed = GPIO_SPEED_FREQ_VERY_HIGH;
  HAL_GPIO_Init(VSYNC_FREQ_GPIO_Port, &GPIO_InitStruct);

  /*Configure GPIO pin : LCD_BL_CTRL_Pin */
  GPIO_InitStruct.Pin = LCD_BL_CTRL_Pin;
  GPIO_InitStruct.Mode = GPIO_MODE_OUTPUT_PP;
  GPIO_InitStruct.Pull = GPIO_NOPULL;
  GPIO_InitStruct.Speed = GPIO_SPEED_FREQ_LOW;
  HAL_GPIO_Init(LCD_BL_CTRL_GPIO_Port, &GPIO_InitStruct);

  /*Configure GPIO pin : MCU_ACTIVE_Pin */
  GPIO_InitStruct.Pin = MCU_ACTIVE_Pin;
  GPIO_InitStruct.Mode = GPIO_MODE_OUTPUT_PP;
  GPIO_InitStruct.Pull = GPIO_NOPULL;
  GPIO_InitStruct.Speed = GPIO_SPEED_FREQ_VERY_HIGH;
  HAL_GPIO_Init(MCU_ACTIVE_GPIO_Port, &GPIO_InitStruct);

/* USER CODE BEGIN MX_GPIO_Init_2 */
  GPIO_InitStruct.Pin = GPIO_PIN_3;
  GPIO_InitStruct.Mode = GPIO_MODE_OUTPUT_PP;
  GPIO_InitStruct.Pull = GPIO_NOPULL;
  GPIO_InitStruct.Speed = GPIO_SPEED_LOW;
  HAL_GPIO_Init(GPIOD, &GPIO_InitStruct);

  GPIO_InitStruct.Pin = GPIO_PIN_6;
  GPIO_InitStruct.Mode = GPIO_MODE_OUTPUT_PP;
  GPIO_InitStruct.Pull = GPIO_NOPULL;
  GPIO_InitStruct.Speed = GPIO_SPEED_LOW;
  HAL_GPIO_Init(GPIOE, &GPIO_InitStruct);

  GPIO_InitStruct.Pin = GPIO_PIN_8;
  GPIO_InitStruct.Mode = GPIO_MODE_OUTPUT_PP;
  GPIO_InitStruct.Pull = GPIO_NOPULL;
  GPIO_InitStruct.Speed = GPIO_SPEED_LOW;
  HAL_GPIO_Init(GPIOA, &GPIO_InitStruct);

  GPIO_InitStruct.Pin = GPIO_PIN_1;
  GPIO_InitStruct.Mode = GPIO_MODE_OUTPUT_PP;
  GPIO_InitStruct.Pull = GPIO_NOPULL;
  GPIO_InitStruct.Speed = GPIO_SPEED_LOW;
  HAL_GPIO_Init(GPIOK, &GPIO_InitStruct);

  GPIO_InitStruct.Pin = GPIO_PIN_6;
  GPIO_InitStruct.Mode = GPIO_MODE_OUTPUT_PP;
  GPIO_InitStruct.Pull = GPIO_NOPULL;
  GPIO_InitStruct.Speed = GPIO_SPEED_LOW;
  HAL_GPIO_Init(GPIOA, &GPIO_InitStruct);
/* USER CODE END MX_GPIO_Init_2 */
}

/* USER CODE BEGIN 4 */
void setFreq(uint16_t freq) {
	uint64_t temp = (uint64_t)freq * 0xFFFFFFFF;
	temp = temp / F_SAMP;
	step = (uint32_t) temp;
}
/* USER CODE END 4 */

void StartDefaultTask(void *argument)
{
  /* USER CODE BEGIN 5 */
  /* Infinite loop */
  for(;;)
  {
    osDelay(100);
    //HAL_GPIO_TogglePin(GPIOI, GPIO_PIN_13);

  }
  /* USER CODE END 5 */
}

void playNoteTaskFunction(void *argument)
{
  /* USER CODE BEGIN playNoteTaskFunction */
  /* Infinite loop */
uint16_t note = 0;
uint16_t stateChange = 0;
osStatus_t status;
osStatus_t status1;

  for(;;)
  {
	//note
	status = osMessageQueueGet(noteQueueHandle, &note, NULL, 0U); //wait for message
	if(status == osOK) {
		if(note != 12) {
			uint16_t frequency = frequencies[note];
			setFreq(frequency);
		} else
			step = 0;
	}
	//sound
	status1 = osMessageQueueGet(stateQueueHandle, &stateChange, NULL, 0U); //wait for message
	if(status1 == osOK) {
		state += (stateChange - 1);
		if(state == 3)
			state = 0;
		else if(state > 3)
			state = 2;
		selectedArray = arrayOfSounds[state];
		osMessageQueuePut(soundQueueHandle, &state, 0U, 0U);
	}

    osDelay(1);
  }
  /* USER CODE END playNoteTaskFunction */
}

 /* MPU Configuration */

void MPU_Config(void)
{
  MPU_Region_InitTypeDef MPU_InitStruct = {0};

  /* Disables the MPU */
  HAL_MPU_Disable();

  /** Initializes and configures the Region and the memory to be protected
  */
  MPU_InitStruct.Enable = MPU_REGION_ENABLE;
  MPU_InitStruct.Number = MPU_REGION_NUMBER0;
  MPU_InitStruct.BaseAddress = 0x24000000;
  MPU_InitStruct.Size = MPU_REGION_SIZE_512KB;
  MPU_InitStruct.SubRegionDisable = 0x0;
  MPU_InitStruct.TypeExtField = MPU_TEX_LEVEL0;
  MPU_InitStruct.AccessPermission = MPU_REGION_FULL_ACCESS;
  MPU_InitStruct.DisableExec = MPU_INSTRUCTION_ACCESS_DISABLE;
  MPU_InitStruct.IsShareable = MPU_ACCESS_NOT_SHAREABLE;
  MPU_InitStruct.IsCacheable = MPU_ACCESS_CACHEABLE;
  MPU_InitStruct.IsBufferable = MPU_ACCESS_BUFFERABLE;

  HAL_MPU_ConfigRegion(&MPU_InitStruct);

  /** Initializes and configures the Region and the memory to be protected
  */
  MPU_InitStruct.Number = MPU_REGION_NUMBER1;
  MPU_InitStruct.BaseAddress = 0x90000000;
  MPU_InitStruct.Size = MPU_REGION_SIZE_256MB;
  MPU_InitStruct.AccessPermission = MPU_REGION_NO_ACCESS;
  MPU_InitStruct.IsCacheable = MPU_ACCESS_NOT_CACHEABLE;
  MPU_InitStruct.IsBufferable = MPU_ACCESS_NOT_BUFFERABLE;

  HAL_MPU_ConfigRegion(&MPU_InitStruct);

  /** Initializes and configures the Region and the memory to be protected
  */
  MPU_InitStruct.Number = MPU_REGION_NUMBER2;
  MPU_InitStruct.Size = MPU_REGION_SIZE_128MB;
  MPU_InitStruct.AccessPermission = MPU_REGION_FULL_ACCESS;
  MPU_InitStruct.DisableExec = MPU_INSTRUCTION_ACCESS_ENABLE;
  MPU_InitStruct.IsCacheable = MPU_ACCESS_CACHEABLE;
  MPU_InitStruct.IsBufferable = MPU_ACCESS_BUFFERABLE;

  HAL_MPU_ConfigRegion(&MPU_InitStruct);

  /** Initializes and configures the Region and the memory to be protected
  */
  MPU_InitStruct.Number = MPU_REGION_NUMBER3;
  MPU_InitStruct.BaseAddress = 0xD0000000;
  MPU_InitStruct.Size = MPU_REGION_SIZE_256MB;
  MPU_InitStruct.AccessPermission = MPU_REGION_NO_ACCESS;
  MPU_InitStruct.DisableExec = MPU_INSTRUCTION_ACCESS_DISABLE;
  MPU_InitStruct.IsCacheable = MPU_ACCESS_NOT_CACHEABLE;
  MPU_InitStruct.IsBufferable = MPU_ACCESS_NOT_BUFFERABLE;

  HAL_MPU_ConfigRegion(&MPU_InitStruct);

  /** Initializes and configures the Region and the memory to be protected
  */
  MPU_InitStruct.Number = MPU_REGION_NUMBER4;
  MPU_InitStruct.Size = MPU_REGION_SIZE_32MB;
  MPU_InitStruct.AccessPermission = MPU_REGION_FULL_ACCESS;
  MPU_InitStruct.IsCacheable = MPU_ACCESS_CACHEABLE;

  HAL_MPU_ConfigRegion(&MPU_InitStruct);
  /* Enables the MPU */
  HAL_MPU_Enable(MPU_PRIVILEGED_DEFAULT);

}

void HAL_TIM_PeriodElapsedCallback(TIM_HandleTypeDef *htim)
{
  if (htim->Instance == TIM6) {
    HAL_IncTick();
  }
  /* USER CODE BEGIN Callback 1 */
  if (htim->Instance == TIM5) {
  	  GPIOK->BSRR = (uint32_t)GPIO_PIN_1 << 16U; //latch enable low
  	  start = TIM1->CNT;
  	  while((TIM1->CNT - start) < 4);

  	  //DATA SEND
  	  //-------------------------------------
  	  bitmask = (1 << 23);
  	  while(bitmask) {
  		  if (bitmask & outData)
  			  GPIOA->BSRR = GPIO_PIN_6; //set data
  		  else
  			  GPIOA->BSRR = (uint32_t)GPIO_PIN_6 << 16U; //reset data

  		  start = TIM1->CNT;
  		  while((TIM1->CNT - start) < 8);
  		  GPIOA->BSRR = GPIO_PIN_8; //set clock

  		  start = TIM1->CNT;
  		  while((TIM1->CNT - start) < 8);
  		  GPIOA->BSRR = (uint32_t)GPIO_PIN_8 << 16U; //reset clock

  		  bitmask = bitmask >> 1;
  	  }

  	  GPIOA->BSRR = (uint32_t)GPIO_PIN_6 << 16U; //reset data
  	  //-------------------------------------

  	  start = TIM1->CNT;
  	  while((TIM1->CNT - start) < 4);
  	  GPIOK->BSRR = GPIO_PIN_1; //latch enable high

  	  //calculate next value
  	  tableIndex += step;
  	  outData = (uint32_t) selectedArray[tableIndex >> 22];
    }
  /* USER CODE END Callback 1 */
}

void Error_Handler(void)
{
}
